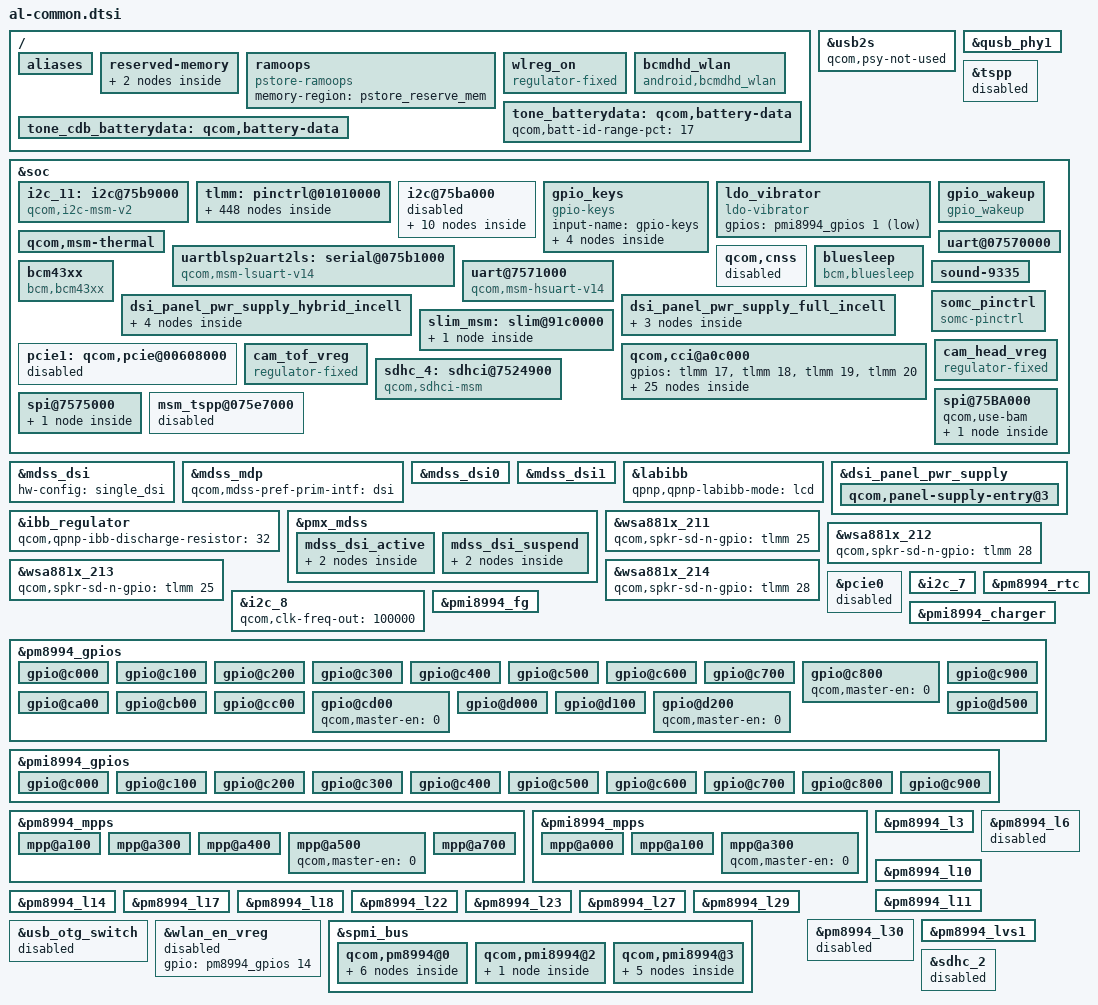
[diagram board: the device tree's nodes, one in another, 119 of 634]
/* 2017-11-15: File added by Sony Corporation */
/*
 * common dts for AL platforms
 *
 * Copyright 2017 Sony Corporation
 *
 * Original code is somc_tone-cdb-specific.dtsi and somc_tone-common.dtsi
 */
/* Copyright (c) 2012-2013, The Linux Foundation. All rights reserved.
 *
 * This program is free software; you can redistribute it and/or modify
 * it under the terms of the GNU General Public License version 2 and
 * only version 2 as published by the Free Software Foundation.
 *
 * This program is distributed in the hope that it will be useful,
 * but WITHOUT ANY WARRANTY; without even the implied warranty of
 * MERCHANTABILITY or FITNESS FOR A PARTICULAR PURPOSE.  See the
 * GNU General Public License for more details.
 */

#include "msm8996-mtp-for-somc.dtsi"
#include "msm8996-mdss-panels-for-somc.dtsi"

/ {
	aliases {
		uart2 = &blsp1_uart2;
		uart3 = &blsp1_uart3;
		i2c11 = &i2c_11;
		sdhc4 = &sdhc_4;
	};

	reserved-memory {
		debug_region: debug_region@83300000 {
			compatible = "removed-dma-pool", "qcom,debug_memory";
			no-map;
			reg = <0 0x83300000 0 0x100000>;
			label = "debug_mem";
		};

		pstore_reserve_mem: pstore_reserve_mem_region_region@83200000 {
			compatible = "removed-dma-pool";
			no-map;
			reg = <0 0x83200000 0 0x100000>;
		};
	};

	ramoops {
		compatible = "pstore-ramoops";
		memory-region = <&pstore_reserve_mem>;
	};
};

/* usb2s config */
&usb2s {
	status = "ok";
	qcom,psy-not-used;
};

&qusb_phy1 {
	/delete-property/ qcom,hold-reset;
};

&tspp {
	status = "disabled";
};



/* for bcmdhd */
/ {
	wlreg_on: wlreg_on {
		compatible = "regulator-fixed";
		regulator-name = "wlreg_on";
		gpio = <&tlmm 84 0>;
		regulator-min-microvolt = <1800000>;
		regulator-max-microvolt = <1800000>;
		startup-delay-us = <100>;
		enable-active-high;
	};
	bcmdhd_wlan: bcmdhd_wlan {
		compatible = "android,bcmdhd_wlan";
		gpios = <&tlmm 79 0x00>; /* WL_HOST_WAKE */
		wlreg_on-supply = <&wlreg_on>;
	};
};

&soc {
	/* I2C : BLSP11 */
	i2c_11: i2c@75b9000 { /* BLSP2 QUP4 */
		compatible = "qcom,i2c-msm-v2";
		#address-cells = <1>;
		#size-cells = <0>;
		reg-names = "qup_phys_addr";
		reg = <0x75b9000 0x1000>;
		interrupt-names = "qup_irq";
		interrupts = <0 105 0>;
		dmas = <&dma_blsp2 20 64 0x20000020 0x20>,
			<&dma_blsp2 21 32 0x20000020 0x20>;
		dma-names = "tx", "rx";
		qcom,master-id = <84>;
		qcom,clk-freq-out = <400000>;
		qcom,clk-freq-in  = <19200000>;
		clock-names = "iface_clk", "core_clk";
		clocks = <&clock_gcc clk_gcc_blsp2_ahb_clk>,
				<&clock_gcc clk_gcc_blsp2_qup5_i2c_apps_clk>;
		pinctrl-names = "i2c_active", "i2c_sleep";
		pinctrl-0 = <&i2c_11_active>;
		pinctrl-1 = <&i2c_11_sleep>;
	};

	tlmm: pinctrl@01010000 {
		i2c_11 {
			i2c_11_active: i2c_11_active {
				mux {
					pins = "gpio60", "gpio61";
					function = "blsp_i2c11";
				};

				config {
					pins = "gpio60", "gpio61";
					drive-strength = <4>;
					bias-disable;
				};
			};

			i2c_11_sleep: i2c_11_sleep {
				mux {
					pins = "gpio60", "gpio61";
					function = "blsp_i2c11";
				};

				config {
					pins = "gpio60", "gpio61";
					drive-strength = <4>;
					bias-pull-up;
				};
			};
		};
	};

	/* I2C : BLSP12 */
	i2c@75ba000 {
		pinctrl-0 = <&msm_gpio_87_act &msm_gpio_88_act>;
		pinctrl-1 = <&msm_gpio_87_sus &msm_gpio_88_sus>;
		status = "disabled";

		/delete-node/ synaptics@20;
		synaptics_clearpad@2c {
			compatible = "synaptics,clearpad";
			reg = <0x2c>;
			interrupt-parent = <&tlmm>;
			interrupts = <125 0x2>;
			synaptics,irq_gpio = <&tlmm 125 0x00>;
			post_probe_start = <0>;
			synaptics,firmware_name = "touch_module_id_0x%02x.img";
			flash_on_post_probe = <1>;
			flip_config = <0>;
			watchdog_enabled = <1>;
			watchdog_delay_ms = <3000>;
			charger_supported = <0>;
			pen_supported = <0>;
			glove_supported = <1>;
			cover_supported = <1>;
			touch_pressure_enabled = <1>;
			touch_size_enabled = <0>;
			touch_orientation_enabled = <0>;
			preset_x_max = <1079>;
			preset_y_max = <1919>;
			preset_n_fingers = <10>;
			wakeup_gesture_supported = <1>;
			wakeup_gesture_lpm_disabled = <1>;
			wakeup_gesture_timeout = <0>;
			wakeup_gesture_use_workaround_for_felica = <1>;
			chip_id = <0x38>;
			wakeup_gesture {
				double_tap {
					gesture_code = <0x0003>;
					event_00 {
						type = <2>; /* LOG */
						message = "=== DOUBLE TAP ===";
					};
					event_01 {
						type = <1>; /* KEY */
						code = <531>; /* TOUCHPAD_ON */
						down = <1>;
					};
					event_02 {
						type = <1>; /* KEY */
						code = <531>; /* TOUCHPAD_ON */
						down = <0>;
					};
					event_03 {
						type = <99>; /* END */
					};
				};
			};
			/* chip settings */
			clearpad_default {
				flash_default_timeout_ms = <20000>;
				calibrate_on_fwflash = <0>;
				calibration_supported = <0>;
				hwreset_delay_for_powerup_ms = <60>;
				interrupt_default_wait_ms = <1000>;
			};
			S3330 {
				flash_default_timeout_ms = <20000>;
				calibrate_on_fwflash = <0>;
				calibration_supported = <0>;
				hwreset_delay_for_powerup_ms = <60>;
				interrupt_default_wait_ms = <1000>;
			};
			S332U {
				flash_default_timeout_ms = <20000>;
				calibration_supported = <1>;
				hwreset_delay_for_powerup_ms = <60>;
				interrupt_default_wait_ms = <1000>;
				calibrate_on_fwflash = <0>;
			};
		};
	};

	gpio_keys {
		compatible = "gpio-keys";
		input-name = "gpio-keys";

		vol_dn {
			label = "volume_down";
			gpios = <&pm8994_gpios 2 0x1>;
			linux,input-type = <1>;
			linux,code = <114>;
			/delete-property/ gpio-key,wakeup;
			debounce-interval = <15>;
		};

		vol_up {
			label = "volume_up";
			gpios = <&pm8994_gpios 3 0x1>;
			linux,input-type = <1>;
			linux,code = <115>;
			/delete-property/ gpio-key,wakeup;
			debounce-interval = <15>;
		};

		cam_snapshot {
			label = "cam_snapshot";
			gpios = <&pm8994_gpios 4 0x1>;
			linux,input-type = <1>;
			linux,code = <0x2fe>;
			gpio-key,wakeup;
			debounce-interval = <15>;
		};

		cam_focus {
			label = "cam_focus";
			gpios = <&pm8994_gpios 5 0x1>;
			linux,input-type = <1>;
			linux,code = <0x210>;
			gpio-key,wakeup;
			debounce-interval = <15>;
		};
	};

	ldo_vibrator {
		compatible = "ldo-vibrator";
		gpios = <&pmi8994_gpios 1 1>;
	};

	gpio_wakeup {
		compatible = "gpio_wakeup";
		irq_gpio_num = <4>;
		irq_gpios = <9 77 117 125>;
	};

	qcom,msm-thermal {
		qcom,limit-temp = <85>;
		qcom,core-limit-temp = <95>;
        };

	/* UART: BLSP9 */
	uartblsp2uart2ls: serial@075b1000 {
		compatible = "qcom,msm-lsuart-v14";
		reg = <0x75b1000 0x1000>;
		interrupts = <0 115 0>;
		clocks = <&clock_gcc clk_gcc_blsp2_uart3_apps_clk>,
			 <&clock_gcc clk_gcc_blsp2_ahb_clk>;
		clock-names = "core_clk", "iface_clk";
		status = "ok";
		pinctrl-names = "default";
		pinctrl-0 = <&msm_gpio_49 &msm_gpio_50>;
	};

        /* UART: BLSP2 */
	uart@07570000 {
		reg = <0x07570000 0x1000>,
		      <0x7544000 0x2b000>;
		interrupt-map = <0 &intc 0 0 108 0
		                1 &intc 0 0 238 0
		                2 &tlmm 42 0>;
		/delete-property/ qcom,inject-rx-on-wakeup;
		/delete-property/ qcom,rx-char-to-inject;
		qcom,bam-tx-ep-pipe-index = <2>;
		qcom,bam-rx-ep-pipe-index = <3>;
		pinctrl-names = "default", "sleep", "on";
		pinctrl-0 = <&msm_gpio_41_suspend &msm_gpio_42_suspend &msm_gpio_43_suspend &msm_gpio_44_suspend>;
		pinctrl-1 = <&msm_gpio_41_suspend &msm_gpio_42_suspend &msm_gpio_43_suspend &msm_gpio_44_suspend>;
		pinctrl-2 = <&msm_gpio_41_active &msm_gpio_42_active &msm_gpio_43_active &msm_gpio_44_active>;
		status = "okay";
	};

	qcom,cnss {
		status = "disable";
	};

	uart@7571000 {
		compatible = "qcom,msm-hsuart-v14";
		reg = <0x7571000 0x1000>,
		    <0x7544000 0x2b000>;
		interrupt-parent = <&blsp1_uart3>;
		interrupt-map = <0 &intc 0 0 109 0
		                1 &intc 0 0 238 0
		                2 &tlmm 46 0>;
		/delete-property/ qcom,inject-rx-on-wakeup;
		/delete-property/ qcom,rx-char-to-inject;
		pinctrl-names = "default", "sleep", "on";
		pinctrl-0 = <&msm_gpio_45_suspend &msm_gpio_46_suspend &msm_gpio_47_suspend &msm_gpio_48_suspend>;
		pinctrl-1 = <&msm_gpio_45_suspend &msm_gpio_46_suspend &msm_gpio_47_suspend &msm_gpio_48_suspend>;
		pinctrl-2 = <&msm_gpio_45_active &msm_gpio_46_active &msm_gpio_47_active &msm_gpio_48_active>;
		status = "okay";
	};

	bluesleep {
		compatible = "bcm,bluesleep";
		bt_host_wake = <&tlmm 82 0x00>; /* BT_HOST_WAKE */
		bt_ext_wake = <&tlmm 81 0x00>; /* BT_DEV_WAKE */
		interrupt-parent = <&tlmm>;
		interrupts = <82 0>;
		interrupt-names = "host_wake";
		pinctrl-names = "wake_irq_active", "wake_irq_suspend";
		pinctrl-0 = <&msm_gpio_82_active &msm_gpio_81>;
		pinctrl-1 = <&msm_gpio_82_suspend &msm_gpio_81>;
	};

	bcm43xx {
		compatible = "bcm,bcm43xx";
		bcm,reg-on-gpio = <&tlmm 83 0x00>; /* BT_REG_ON */
		pinctrl-names = "default", "sleep";
		pinctrl-0 = <&msm_gpio_83>;
		pinctrl-1 = <&msm_gpio_83>;
	};

	dsi_panel_pwr_supply_hybrid_incell: dsi_panel_pwr_supply_hybrid_incell {
		#address-cells = <1>;
		#size-cells = <0>;

		qcom,panel-supply-entry@0 {
			reg = <0>;
			qcom,supply-name = "vddio";
			qcom,supply-min-voltage = <1800000>;
			qcom,supply-max-voltage = <1800000>;
			qcom,supply-enable-load = <62000>;
			qcom,supply-disable-load = <80>;
		};

		qcom,panel-supply-entry@1 {
			reg = <1>;
			qcom,supply-name = "lab";
			qcom,supply-min-voltage = <4600000>;
			qcom,supply-max-voltage = <6000000>;
			qcom,supply-enable-load = <100000>;
			qcom,supply-disable-load = <100>;
		};

		qcom,panel-supply-entry@2 {
			reg = <2>;
			qcom,supply-name = "ibb";
			qcom,supply-min-voltage = <4600000>;
			qcom,supply-max-voltage = <6000000>;
			qcom,supply-enable-load = <100000>;
			qcom,supply-disable-load = <100>;
		};

		qcom,panel-supply-entry@3 {
			reg = <2>;
			qcom,supply-name = "touch-avdd";
			qcom,supply-min-voltage = <2800000>;
			qcom,supply-max-voltage = <3200000>;
			qcom,supply-enable-load = <100000>;
			qcom,supply-disable-load = <100>;
		};
	};

	dsi_panel_pwr_supply_full_incell: dsi_panel_pwr_supply_full_incell {
		#address-cells = <1>;
		#size-cells = <0>;

		qcom,panel-supply-entry@0 {
			reg = <0>;
			qcom,supply-name = "vddio";
			qcom,supply-min-voltage = <1800000>;
			qcom,supply-max-voltage = <1800000>;
			qcom,supply-enable-load = <62000>;
			qcom,supply-disable-load = <80>;
		};

		qcom,panel-supply-entry@1 {
			reg = <1>;
			qcom,supply-name = "lab";
			qcom,supply-min-voltage = <4600000>;
			qcom,supply-max-voltage = <6000000>;
			qcom,supply-enable-load = <100000>;
			qcom,supply-disable-load = <100>;
		};

		qcom,panel-supply-entry@2 {
			reg = <2>;
			qcom,supply-name = "ibb";
			qcom,supply-min-voltage = <4600000>;
			qcom,supply-max-voltage = <6000000>;
			qcom,supply-enable-load = <100000>;
			qcom,supply-disable-load = <100>;
		};

		/delete-node/ qcom,panel-supply-entry@3;
	};

	pcie1: qcom,pcie@00608000 {
		status = "disabled";
	};

	sound-9335 {
		qcom,msm-mbhc-hphl-swh = <1>;
		/delete-property/ qcom,hph-en1-gpio;
		/delete-property/ qcom,hph-en0-gpio;
		/delete-property/ qcom,us-euro-gpios;
		qcom,ear-en-gpios = <&pm8994_gpios 13 0>;
		qcom,audio-routing =
			"AIF4 VI", "MCLK",
			"RX_BIAS", "MCLK",
			"LDO_H", "MCLK",
			"AMIC1", "MIC BIAS1",
			"MIC BIAS1", "Handset Mic",
			"AMIC2", "MIC BIAS2",
			"MIC BIAS2", "Headset Mic",
			"AMIC3", "MIC BIAS3",
			"MIC BIAS3", "ANCRight Headset Mic",
			"AMIC4", "MIC BIAS4",
			"MIC BIAS4", "ANCLeft Headset Mic",
			"LDO_H", "AHC VSNS",
			"DMIC0", "MIC BIAS1",
			"MIC BIAS1", "Digital Mic0",
			"DMIC3", "MIC BIAS4",
			"MIC BIAS4", "Digital Mic3",
			"SpkrLeft IN", "SPK1 OUT";
	};

	slim_msm: slim@91c0000 {
		tasha_codec {
			qcom,cdc-micbias1-mv = <2000>;
			qcom,cdc-micbias2-mv = <2000>;
			qcom,cdc-micbias3-mv = <2000>;
			qcom,cdc-micbias4-mv = <2000>;
			qcom,cdc-dmic-sample-rate = <2400000>;
		};
	};

	somc_pinctrl: somc_pinctrl {
		compatible = "somc-pinctrl";
		pinctrl-names = "platform_common_default",
				"product_common_default",
				"variant_default";
		pinctrl-0 = <&msm_gpio_4
				&msm_gpio_5 &msm_gpio_6 &msm_gpio_7 &msm_gpio_8 &msm_gpio_9
				&msm_gpio_10 &msm_gpio_11 &msm_gpio_12 &msm_gpio_13
				&msm_gpio_14 &msm_gpio_15 &msm_gpio_16 &msm_gpio_17
				&msm_gpio_18 &msm_gpio_19 &msm_gpio_20 &msm_gpio_21
				&msm_gpio_22 &msm_gpio_23 &msm_gpio_24 &msm_gpio_25
				&msm_gpio_26 &msm_gpio_27 &msm_gpio_28 &msm_gpio_29
				&msm_gpio_30 &msm_gpio_31 &msm_gpio_32 &msm_gpio_33
				&msm_gpio_34 &msm_gpio_35 &msm_gpio_38 &msm_gpio_39 &msm_gpio_40
				&msm_gpio_41_suspend &msm_gpio_42_suspend &msm_gpio_43_suspend &msm_gpio_44_suspend
				&msm_gpio_45_suspend &msm_gpio_46_suspend &msm_gpio_47_suspend &msm_gpio_48_suspend
				&msm_gpio_49 &msm_gpio_50 &msm_gpio_51 &msm_gpio_52
				&msm_gpio_55 &msm_gpio_56 &msm_gpio_57 &msm_gpio_58
				&msm_gpio_59 &msm_gpio_60 &msm_gpio_61 &msm_gpio_62
				&msm_gpio_63 &msm_gpio_69 &msm_gpio_73 &msm_gpio_74
				&msm_gpio_75 &msm_gpio_76 &msm_gpio_77 &msm_gpio_78
				&msm_gpio_79 &msm_gpio_80 &msm_gpio_81 &msm_gpio_82_suspend &msm_gpio_83
				&msm_gpio_84 &msm_gpio_89 &msm_gpio_90
				&msm_gpio_108 &msm_gpio_112 &msm_gpio_116
				&msm_gpio_118 &msm_gpio_119
				&msm_gpio_121 &msm_gpio_122 &msm_gpio_123 &msm_gpio_124
				&msm_gpio_125 &msm_gpio_126 &msm_gpio_127 &msm_gpio_128
				&msm_gpio_130 &msm_gpio_131
				&msm_gpio_132 &msm_gpio_138 &msm_gpio_141 &msm_gpio_142 &msm_gpio_143>;

		/* If product common default setting is needed,
		   fill pinctrl-1 value in <product>_common.dtsi */
		pinctrl-1 = <&msm_gpio_105 &msm_gpio_110 &msm_gpio_111>;

		/* If variant specific default setting is needed,
		   fill pinctrl-2 value in <variant>.dtsi */
		pinctrl-2 = <>;

		/* If variant specific default setting is needed,
		   fill pinctrl-3 value in <variant>.dtsi */
		pinctrl-3 = <>;
	};

	qcom,cci@a0c000 {
		gpios = <&tlmm 17 0>,
			<&tlmm 18 0>,
			<&tlmm 19 0>,
			<&tlmm 20 0>;

		qcom,i2c_fast_mode {
			qcom,hw-thigh = <43>;
			qcom,hw-tlow = <64>;
			qcom,hw-tsu-sto = <41>;
			qcom,hw-tsu-sta = <41>;
			qcom,hw-thd-dat = <25>;
			qcom,hw-thd-sta = <35>;
			qcom,hw-tbuf = <64>;
			qcom,hw-scl-stretch-en = <0>;
			qcom,hw-trdhld = <6>;
			qcom,hw-tsp = <3>;
			qcom,cci-clk-src = <37500000>;
			status = "ok";
		};

		qcom,i2c_fast_plus_mode {
			qcom,hw-thigh = <16>;
			qcom,hw-tlow = <22>;
			qcom,hw-tsu-sto = <17>;
			qcom,hw-tsu-sta = <18>;
			qcom,hw-thd-dat = <16>;
			qcom,hw-thd-sta = <15>;
			qcom,hw-tbuf = <19>;
			qcom,hw-scl-stretch-en = <1>;
			qcom,hw-trdhld = <3>;
			qcom,hw-tsp = <3>;
			qcom,cci-clk-src = <37500000>;
			status = "ok";
		};

		qcom,camera@0 {
			cell-index = <0>;
			compatible = "qcom,sony_camera_0";
			reg = <0x0>;
			status = "ok";
			qcom,slave-id = <0x20 0x0 0x0000>;
			qcom,csiphy-sd-index = <0>;
			qcom,csid-sd-index = <0>;
			qcom,mount-angle = <0>;
			qcom,sensor-name = "sony_camera_0";
			cam_vdig-supply = <&pm8994_l3>;
			cam_vana-supply = <&pm8994_l17>;
			cam_vio-supply = <&pm8994_lvs1>;
			qcom,cam-vreg-name = "cam_vdig", "cam_vana", "cam_vio";
			qcom,cam-vreg-type = <0 0 1 0>;
			qcom,cam-vreg-min-voltage = <1000000 2700000 0>;
			qcom,cam-vreg-max-voltage = <1000000 2700000 0>;
			qcom,cam-vreg-op-mode = <105000 85600 0>;
			qcom,gpio-no-mux = <0>;
			pinctrl-names = "cam_default", "cam_suspend";
			pinctrl-0 = <&cam_sensor_mclk0_active &cam_sensor_rear_active>;
			pinctrl-1 = <&cam_sensor_mclk0_suspend &cam_sensor_rear_suspend>;
			gpios = <&tlmm 13 0>, <&tlmm 30 0>;
			qcom,gpio-reset = <1>;
			qcom,gpio-req-tbl-num = <0 1>;
			qcom,gpio-req-tbl-flags = <1 0>;
			qcom,gpio-req-tbl-label = "CAMIF_MCLK0", "CAM_RESET0";
			qcom,csi-lane-assign = <0x4320>;
			qcom,csi-lane-mask = <0x1F>;
			qcom,sensor-position = <0>;
			qcom,sensor-mode = <1>;
			qcom,cci-master = <0>;
			clocks = <&clock_mmss clk_mclk0_clk_src>, <&clock_mmss clk_camss_mclk0_clk>;
			clock-names = "cam_src_clk", "cam_clk";
			sony,i2c_addr = <0x20>;
			sony,eeprom_addr = <0xA8>;
			sony,eeprom_type = <3>;
			sony,eeprom_max_len = <2048>;
			sony,gpio_af = <0>;
			sony,subdev_code = <0x3007>;
			sony_camera_module_0: sony,camera_modules {
			};
		};

		qcom,camera@1 {
			cell-index = <1>;
			compatible = "qcom,sony_camera_1";
			reg = <0x1>;
			status = "ok";
			qcom,slave-id = <0x20 0x0000 0x0000>;
			qcom,csiphy-sd-index = <1>;
			qcom,csid-sd-index = <1>;
			qcom,mount-angle = <0>;
			qcom,sensor-name = "sony_camera_1";
			cam_vdig-supply = <&cam_head_vreg>;
			cam_vana-supply = <&cam_head_vreg>;
			cam_vio-supply = <&pm8994_lvs1>;
			qcom,cam-vreg-name = "cam_vdig", "cam_vio";
			qcom,cam-vreg-type = <0 1>;
			qcom,cam-vreg-min-voltage = <0 0>;
			qcom,cam-vreg-max-voltage = <0 0>;
			qcom,cam-vreg-op-mode = <0 0>;
			qcom,gpio-no-mux = <0>;
			pinctrl-names = "cam_default", "cam_suspend";
			pinctrl-0 = <&cam_sensor_mclk1_active &cam_sensor_front_active>;
			pinctrl-1 = <&cam_sensor_mclk1_suspend &cam_sensor_front_suspend>;
			gpios = <&tlmm 14 0>, <&tlmm 23 0>;
			qcom,gpio-reset = <1>;
			qcom,gpio-req-tbl-num = <0 1>;
			qcom,gpio-req-tbl-flags = <1 0>;
			qcom,gpio-req-tbl-label = "CAMIF_MCLK1", "CAM_RESET1";
			qcom,csi-lane-assign = <0x4320>;
			qcom,csi-lane-mask = <0x1F>;
			qcom,sensor-position = <1>;
			qcom,sensor-mode = <1>;
			qcom,cci-master = <1>;
			clocks = <&clock_mmss clk_mclk1_clk_src>, <&clock_mmss clk_camss_mclk1_clk>;
			clock-names = "cam_src_clk", "cam_clk";
			sony,i2c_addr = <0x20>;
			sony,eeprom_addr = <0xA8>;
			sony,eeprom_type = <3>;
			sony,eeprom_max_len = <2048>;
			sony,gpio_af = <0>;
			sony,subdev_code = <0x3007>;
			sony_camera_module_1: sony,camera_modules {
			};
		};

		qcom,camera@2 {
			cell-index = <2>;
			compatible = "qcom,sony_camera_2";
			reg = <0x2>;
			status = "ok";
			qcom,slave-id = <0x20 0x0000 0x0000>;
			qcom,csiphy-sd-index = <2>;
			qcom,csid-sd-index = <2>;
			qcom,mount-angle = <0>;
			qcom,sensor-name = "sony_camera_2";
			cam_vdig-supply = <&pm8994_l27>;
			cam_vana-supply = <&cam_tof_vreg>; /* TOF_PWR_EN */
			cam_vio-supply = <&pm8994_lvs1>;
			qcom,cam-vreg-name = "cam_vdig", "cam_vana", "cam_vio";
			qcom,cam-vreg-type = <0 0 1>;
			qcom,cam-vreg-min-voltage = <1200000 0 0>;
			qcom,cam-vreg-max-voltage = <1200000 0 0>;
			qcom,cam-vreg-op-mode = <80000 0 0>;
			qcom,gpio-no-mux = <0>;
			pinctrl-names = "cam_default", "cam_suspend";
			pinctrl-0 = <&cam_sensor_mclk2_active &cam_sensor_front2_active>;
			pinctrl-1 = <&cam_sensor_mclk2_suspend &cam_sensor_front2_suspend>;
			gpios = <&tlmm 15 0>, <&tlmm 26 0>, <&tlmm 8 0>, <&tlmm 69 0>;
			qcom,gpio-reset = <1>;
			qcom,gpio-req-tbl-num = <0 1 2 3>;
			qcom,gpio-req-tbl-flags = <1 0 0 0>;
			qcom,gpio-req-tbl-label = "CAMIF_MCLK2", "CAM_RESET2", "CAM_HV_EN", "CAM_LD_EN";
			qcom,csi-lane-assign = <0x4320>;
			qcom,csi-lane-mask = <0x1F>;
			qcom,sensor-position = <2>;
			qcom,sensor-mode = <1>;
			qcom,cci-master = <1>;
			clocks = <&clock_mmss clk_mclk2_clk_src>, <&clock_mmss clk_camss_mclk2_clk>;
			clock-names = "cam_src_clk", "cam_clk";
			sony,i2c_addr = <0x20>;
			sony,eeprom_addr = <0xA0>;
			sony,eeprom_type = <255>;
			sony,eeprom_max_len = <2048>;
			sony,gpio_af = <0>;
			sony,subdev_code = <0x3007>;
			sony_camera_module_2: sony,camera_modules {
			};
		};
	};

	cam_head_vreg: cam_head_vreg {
		compatible = "regulator-fixed";
		regulator-name = "cam_head_vreg";
		startup-delay-up = <0>;
		enable-active-high;
		gpio = <&tlmm 22 0>;
	};

	cam_tof_vreg: cam_tof_vreg {
		compatible = "regulator-fixed";
		regulator-name = "cam_tof_vreg";
		startup-delay-up = <0>;
		enable-active-high;
		gpio = <&tlmm 24 0>;
	};

	/* sdc4 */
	sdhc_4: sdhci@7524900 {
		compatible = "qcom,sdhci-msm";
		reg = <0x7524900 0x314>, <0x7524000 0x800>;
		reg-names = "hc_mem", "core_mem";

		interrupts = <0 129 0>, <0 227 0>, <0 228 0>;
		interrupt-names = "hc_irq", "pwr_irq", "sdiowakeup_irq";

		clock-names = "iface_clk", "core_clk";
		clocks = <&clock_gcc clk_gcc_sdcc4_ahb_clk>,
		<&clock_gcc clk_gcc_sdcc4_apps_clk>;

		qcom,large-address-bus;
		qcom,bus-width = <4>;

		qcom,msm-bus,name = "sdhc4";
		qcom,msm-bus,num-cases = <9>;
		qcom,msm-bus,num-paths = <1>;
		qcom,msm-bus,vectors-KBps = <80 512 0 0>, /* No vote */
			<80 512 1600 3200>, /* 400 KB/s*/
			<80 512 80000 160000>, /* 20 MB/s */
			<80 512 100000 200000>, /* 25 MB/s */
			<80 512 200000 400000>, /* 50 MB/s */
			<80 512 400000 800000>, /* 100 MB/s */
			<80 512 400000 800000>, /* 200 MB/s */
			<80 512 400000 800000>, /* 400 MB/s */
			<80 512 2048000 4096000>; /* Max. bandwidth */
		qcom,bus-bw-vectors-bps = <0 400000 20000000 25000000 50000000
			100000000 200000000 400000000 4294967295>;

		qcom,pm-qos-cpu-groups = <0x03 0x0c>;
		qcom,pm-qos-cmdq-latency-us = <70 70>, <70 70>;
		qcom,pm-qos-legacy-latency-us = <70 70>, <70 70>;
		qcom,pm-qos-irq-type = "affine_cores";
		qcom,pm-qos-irq-cpu = <0>;
		qcom,pm-qos-irq-latency = <70 70>;
		status = "ok";
		vdd-io-supply = <&pm8994_s4>;
		qcom,vdd-io-voltage-level = <1800000 1800000>;
		qcom,vdd-io-current-level = <200 15000>;
		qcom,vdd-io-always-on;
		pinctrl-names = "active", "sleep";
		pinctrl-0 = <&sdc4_clk_on &sdc4_cmd_on &sdc4_data0_on &sdc4_data1_on
			&sdc4_data2_on &sdc4_data3_on>;
		pinctrl-1 = <&sdc4_clk_off &sdc4_cmd_off &sdc4_data0_off &sdc4_data1_off
			&sdc4_data2_off &sdc4_data3_off>;
		qcom,clk-rates = <400000 20000000 25000000 50000000 100000000>;
		qcom,bus-speed-mode = "SDR12", "SDR25", "SDR50", "DDR50";
		qcom,nonremovable;
		qcom,core_3_0v_support;
		cd-post;
		wifi-host;
	};

	/* SPI : BLSP12 */
	spi@75BA000{
		status = "okay";
		qcom,use-bam;
		eye0@0 {
			compatible="spidev";
			reg = <0>;
			spi-max-frequency =<38400000>;
		};
	};
	/* SPI : BLSP1 */
	spi@7575000 {
		status = "okay";
		qcom,use-bam;
		pinctrl-0 = <&spi_0_active>;
		pinctrl-1 = <&spi_0_sleep>;
		eye0@0 {
			compatible="spidev";
			reg = <0>;
			spi-max-frequency =<38400000>;
		};
	};

	/* disable tspp */
	msm_tspp@075e7000 {
		status = "disable";
	};
};

&sony_camera_module_0 {
	module_names = "LGI20BS0", "SUN20BS0";
	default_module_name = "LGI20BS0";

	LGI20BS0 {
		mount_angle = <90>;
		sensor_rotation = <0>;
		sensor_facing = <0>;
		total_pixel_number_w = <5264>;
		total_pixel_number_h = <3992>;
		active_pixel_number_x = <656>;
		active_pixel_number_y = <0>;
		active_pixel_number_w = <3936>;
		active_pixel_number_h = <3936>;
		min_focus_distance = <0>;
		hyper_focal_distance = <3679>;
		diagonal_len = "7.87";
		unit_cell_size_w = "1.20";
		unit_cell_size_h = "1.20";
		min_f_number = "2.80";
		max_f_number = "2.80";
		has_3a = <0>;
		has_focus_actuator = <0>;
		need_standby_af = <0>;
		i2c_freq_mode = <1>;
		has_pdaf = <0>;
		has_rs = <1>;
		pdaf_free_area_num = <0>;
		pdaf_fixed_area_size_w = <0>;
		pdaf_fixed_area_size_h = <0>;
		pll_num = <26>;
		pll = <1134 1134 1134 1134 1134 1134 1134 1134 1134 1134 1134 1134 1134 1134 1134 1134 1134 1134 1134 1134 1134 1134 1134 1134 1134 1134>;
		power_off {
			commands =
				"I2C_WRITE",
				"GPIO_RESET",
				"CAM_CLK",
				"CAM_VDIG",
				"CAM_VIO",
				"CAM_VANA",
				"EXIT";
			CAM_VDIG = <0 0xFFFFFFFF 0 1>;
			CAM_VIO = <1 0xFFFFFFFF 0 1>;
			CAM_VANA = <2 0xFFFFFFFF 0 99>;
			GPIO_RESET = <5 0x0 0 1>;
			CAM_CLK = <6 0xFFFFFFFF 0 1>;
			I2C_WRITE = <7 0x0100 0 100>;
			EXIT = <8 0x0 0 0>;
		};
		power_on {
			commands =
				"CAM_VDIG",
				"CAM_VIO",
				"CAM_VANA",
				"CAM_CLK",
				"GPIO_RESET",
				"EXIT";
			CAM_VDIG = <0 1000 76700 1>;
			CAM_VIO = <1 0 0 1>;
			CAM_VANA = <2 2700 39200 1>;
			GPIO_RESET = <5 1 0 1>;
			CAM_CLK = <6 0 0 10>;
			EXIT = <8 0x0 0 0>;
		};
	};

	SUN20BS0 {
		mount_angle = <90>;
		sensor_rotation = <0>;
		sensor_facing = <0>;
		total_pixel_number_w = <5264>;
		total_pixel_number_h = <3992>;
		active_pixel_number_x = <656>;
		active_pixel_number_y = <0>;
		active_pixel_number_w = <3936>;
		active_pixel_number_h = <3936>;
		min_focus_distance = <0>;
		hyper_focal_distance = <3679>;
		diagonal_len = "7.87";
		unit_cell_size_w = "1.20";
		unit_cell_size_h = "1.20";
		min_f_number = "2.80";
		max_f_number = "2.80";
		has_3a = <0>;
		has_focus_actuator = <0>;
		need_standby_af = <0>;
		i2c_freq_mode = <1>;
		has_pdaf = <0>;
		has_rs = <1>;
		pdaf_free_area_num = <0>;
		pdaf_fixed_area_size_w = <0>;
		pdaf_fixed_area_size_h = <0>;
		pll_num = <26>;
		pll = <1134 1134 1134 1134 1134 1134 1134 1134 1134 1134 1134 1134 1134 1134 1134 1134 1134 1134 1134 1134 1134 1134 1134 1134 1134 1134>;
		power_off {
			commands =
				"I2C_WRITE",
				"GPIO_RESET",
				"CAM_CLK",
				"CAM_VDIG",
				"CAM_VIO",
				"CAM_VANA",
				"EXIT";
			CAM_VDIG = <0 0xFFFFFFFF 0 1>;
			CAM_VIO = <1 0xFFFFFFFF 0 1>;
			CAM_VANA = <2 0xFFFFFFFF 0 99>;
			GPIO_RESET = <5 0x0 0 1>;
			CAM_CLK = <6 0xFFFFFFFF 0 1>;
			I2C_WRITE = <7 0x0100 0 100>;
			EXIT = <8 0x0 0 0>;
		};
		power_on {
			commands =
				"CAM_VDIG",
				"CAM_VIO",
				"CAM_VANA",
				"CAM_CLK",
				"GPIO_RESET",
				"EXIT";
			CAM_VDIG = <0 1000 76700 1>;
			CAM_VIO = <1 0 0 1>;
			CAM_VANA = <2 2700 39200 1>;
			GPIO_RESET = <5 1 0 1>;
			CAM_CLK = <6 0 0 10>;
			EXIT = <8 0x0 0 0>;
		};
	};

	qcom,msm-imem@66bf000 {
		#address-cells = <1>;
		#size-cells = <0>;
		debug_base@18 {
			compatible = "qcom,msm-imem-debug_base";
			reg = <0x44 4>;
		};
	};
};

&sony_camera_module_1 {
	module_names = "LGI20BS0", "SUN20BS0";
	default_module_name = "LGI20BS0";

	LGI20BS0 {
		mount_angle = <90>;
		sensor_rotation = <0>;
		sensor_facing = <1>;
		total_pixel_number_w = <5264>;
		total_pixel_number_h = <3992>;
		active_pixel_number_x = <656>;
		active_pixel_number_y = <0>;
		active_pixel_number_w = <3936>;
		active_pixel_number_h = <3936>;
		min_focus_distance = <0>;
		hyper_focal_distance = <3679>;
		diagonal_len = "7.87";
		unit_cell_size_w = "1.20";
		unit_cell_size_h = "1.20";
		min_f_number = "2.80";
		max_f_number = "2.80";
		has_3a = <0>;
		has_focus_actuator = <0>;
		need_standby_af = <0>;
		i2c_freq_mode = <1>;
		has_pdaf = <0>;
		has_rs = <1>;
		pdaf_free_area_num = <0>;
		pdaf_fixed_area_size_w = <0>;
		pdaf_fixed_area_size_h = <0>;
		pll_num = <26>;
		pll = <1134 1134 1134 1134 1134 1134 1134 1134 1134 1134 1134 1134 1134 1134 1134 1134 1134 1134 1134 1134 1134 1134 1134 1134 1134 1134>;
		power_off {
			commands =
				"I2C_WRITE",
				"GPIO_RESET",
				"CAM_CLK",
				"CAM_VDIG",
				"CAM_VIO",
				"CAM_VANA",
				"EXIT";
			CAM_VIO = <1 0xFFFFFFFF 0 1>;
			CAM_VDIG = <0 0xFFFFFFFF 0 99>;
			CAM_VANA = <2 0xFFFFFFFF 0 99>;
			GPIO_RESET = <5 0x0 0 1>;
			CAM_CLK = <6 0xFFFFFFFF 0 1>;
			I2C_WRITE = <7 0x0100 0 100>;
			EXIT = <8 0x0 0 0>;
		};
		power_on {
			commands =
				"CAM_VIO",
				"CAM_VANA",
				"CAM_VDIG",
				"CAM_CLK",
				"GPIO_RESET",
				"EXIT";
			CAM_VIO = <1 0 0 1>;
			CAM_VANA = <2 0 0 1>;
			CAM_VDIG = <0 0 0 1>;
			GPIO_RESET = <5 1 0 1>;
			CAM_CLK = <6 0 0 1>;
			EXIT = <8 0x0 0 0>;
		};
	};

	SUN20BS0 {
		mount_angle = <90>;
		sensor_rotation = <0>;
		sensor_facing = <1>;
		total_pixel_number_w = <5264>;
		total_pixel_number_h = <3992>;
		active_pixel_number_x = <656>;
		active_pixel_number_y = <0>;
		active_pixel_number_w = <3936>;
		active_pixel_number_h = <3936>;
		min_focus_distance = <0>;
		hyper_focal_distance = <3679>;
		diagonal_len = "7.87";
		unit_cell_size_w = "1.20";
		unit_cell_size_h = "1.20";
		min_f_number = "2.80";
		max_f_number = "2.80";
		has_3a = <0>;
		has_focus_actuator = <0>;
		need_standby_af = <0>;
		i2c_freq_mode = <1>;
		has_pdaf = <0>;
		has_rs = <1>;
		pdaf_free_area_num = <0>;
		pdaf_fixed_area_size_w = <0>;
		pdaf_fixed_area_size_h = <0>;
		pll_num = <26>;
		pll = <1134 1134 1134 1134 1134 1134 1134 1134 1134 1134 1134 1134 1134 1134 1134 1134 1134 1134 1134 1134 1134 1134 1134 1134 1134 1134>;
		power_off {
			commands =
				"I2C_WRITE",
				"GPIO_RESET",
				"CAM_CLK",
				"CAM_VDIG",
				"CAM_VIO",
				"CAM_VANA",
				"EXIT";
			CAM_VIO = <1 0xFFFFFFFF 0 1>;
			CAM_VDIG = <0 0xFFFFFFFF 0 99>;
			CAM_VANA = <2 0xFFFFFFFF 0 99>;
			GPIO_RESET = <5 0x0 0 1>;
			CAM_CLK = <6 0xFFFFFFFF 0 1>;
			I2C_WRITE = <7 0x0100 0 100>;
			EXIT = <8 0x0 0 0>;
		};
		power_on {
			commands =
				"CAM_VIO",
				"CAM_VANA",
				"CAM_VDIG",
				"CAM_CLK",
				"GPIO_RESET",
				"EXIT";
			CAM_VIO = <1 0 0 1>;
			CAM_VANA = <2 0 0 1>;
			CAM_VDIG = <0 0 0 1>;
			GPIO_RESET = <5 1 0 1>;
			CAM_CLK = <6 0 0 1>;
			EXIT = <8 0x0 0 0>;
		};
	};
};

&sony_camera_module_2 {
	module_names = "SKTOF000";
	default_module_name = "SKTOF000";

	SKTOF000 {
		mount_angle = <0>;
		sensor_rotation = <0>;
		sensor_facing = <2>;
		total_pixel_number_w = <5264>;
		total_pixel_number_h = <3992>;
		active_pixel_number_x = <8>;
		active_pixel_number_y = <48>;
		active_pixel_number_w = <5248>;
		active_pixel_number_h = <3936>;
		min_focus_distance = <0>;
		hyper_focal_distance = <3679>;
		diagonal_len = "7.87";
		unit_cell_size_w = "1.20";
		unit_cell_size_h = "1.20";
		min_f_number = "2.00";
		max_f_number = "2.00";
		has_3a = <0>;
		has_focus_actuator = <0>;
		need_standby_af = <0>;
		i2c_freq_mode = <1>;
		has_pdaf = <0>;
		has_rs = <1>;
		pdaf_free_area_num = <0>;
		pdaf_fixed_area_size_w = <0>;
		pdaf_fixed_area_size_h = <0>;
		pll_num = <0>;
		pll = <0>;
		power_off {
			commands =
				"GPIO_RESET",
				"CAM_CLK",
				"GPIO_LD",
				"GPIO_HV",
				"CAM_VIO",
				"CAM_VDIG",
				"CAM_VANA",
				"EXIT";
			GPIO_RESET = <5 0x0 0 10>;
			CAM_CLK = <6 0xFFFFFFFF 0 10>;
			GPIO_LD = <10 0 0 1>;
			GPIO_HV = <9 0 0 2>;
			CAM_VIO = <1 0xFFFFFFFF 0 0>;
			CAM_VDIG = <0 0xFFFFFFFF 0 0>;
			CAM_VANA = <2 0xFFFFFFFF 0 100>;
			EXIT = <8 0x0 0 0>;
		};
		power_on {
			commands =
				"CAM_VANA",
				"CAM_VDIG",
				"CAM_VIO",
				"GPIO_HV",
				"GPIO_LD",
				"CAM_CLK",
				"GPIO_RESET",
				"EXIT";
			CAM_VANA = <2 0 0 0>; /* TOF_PWR_EN */
			CAM_VDIG = <0 1200 80000 0>;
			CAM_VIO = <1 0 0 2>;
			GPIO_HV = <9 1 0 1>; /* TOF_HV_PWR_EN */
			GPIO_LD = <10 1 0 100>; /* TOF_LD_EN */
			CAM_CLK = <6 24000000 0 1>;
			GPIO_RESET = <5 1 0 10>;
			EXIT = <8 0x0 0 0>;
		};
	};
};

&mdss_dsi {
	hw-config = "single_dsi";
};

/* Graphics */
&mdss_mdp {
	qcom,mdss-pref-prim-intf = "dsi";
};

&mdss_dsi0 {
	vddio-supply = <&pm8994_s4>;
	touch-avdd-supply = <&pm8994_l22>;
	pinctrl-names = "mdss_default", "mdss_sleep", "mdss_touch_active", "mdss_touch_suspend";
	pinctrl-0 = <&mdss_dsi_active &mdss_te_active>;
	pinctrl-1 = <&mdss_dsi_suspend &mdss_te_suspend>;
	pinctrl-2 = <&mdss_touch_active>;
	pinctrl-3 = <&mdss_touch_suspend>;
	qcom,platform-te-gpio = <&tlmm 10 0>;
	qcom,platform-reset-gpio = <&tlmm 8 0>;
	qcom,platform-vddio-gpio = <&tlmm 51 0>;
	qcom,platform-touch-vddio-gpio = <&tlmm 50 0>;
	qcom,platform-touch-reset-gpio = <&tlmm 89 0>;
	qcom,platform-touch-int-gpio = <&tlmm 125 0>;
};

&mdss_dsi1 {
	vddio-supply = <&pm8994_s4>;
	touch-avdd-supply = <&pm8994_l22>;
	pinctrl-names = "mdss_default", "mdss_sleep";
	pinctrl-0 = <&mdss_dsi_active &mdss_te_active>;
	pinctrl-1 = <&mdss_dsi_suspend &mdss_te_suspend>;
	qcom,platform-te-gpio = <&tlmm 10 0>;
	qcom,platform-reset-gpio = <&tlmm 8 0>;
};

&labibb {
	status = "ok";
	qpnp,qpnp-labibb-mode = "lcd";
};

&ibb_regulator {
	qcom,qpnp-ibb-discharge-resistor = <32>;
};

&dsi_panel_pwr_supply {
		qcom,panel-supply-entry@3 {
			reg = <2>;
			qcom,supply-name = "touch_vdd";
			qcom,supply-min-voltage = <2800000>;
			qcom,supply-max-voltage = <3200000>;
			qcom,supply-enable-load = <100000>;
			qcom,supply-disable-load = <100>;
		};
};

&pmx_mdss {
	mdss_dsi_active: mdss_dsi_active {
		mux {
			pins = "gpio8";
			function = "gpio";
		};

		config {
			pins = "gpio8";
			drive-strength = <2>; /* 2 mA */
			bias-disable = <0>; /* no pull */
			output-high;
		};
	};
	mdss_dsi_suspend: mdss_dsi_suspend {
		mux {
			pins = "gpio8";
			function = "gpio";
		};

		config {
			pins = "gpio8";
			drive-strength = <2>; /* 2 mA */
			/delete-property/ bias-pull-down;
			bias-disable = <0>; /* no pull */
			output-low;
		};
	};
};

/* Audio */
&wsa881x_211 {
	qcom,spkr-sd-n-gpio = <&tlmm 25 0>;
};

&wsa881x_212 {
	qcom,spkr-sd-n-gpio = <&tlmm 28 0>;
};

&wsa881x_213 {
	qcom,spkr-sd-n-gpio = <&tlmm 25 0>;
};

&wsa881x_214 {
	qcom,spkr-sd-n-gpio = <&tlmm 28 0>;
};

/* Wlan */
&pcie0 {
	status = "disabled";
};

/* For Charger */
&i2c_7 {
	/delete-node/ silabs4705@11;
	/delete-node/ smb1351-charger@1d;
};

/* Charger */
/{
	tone_batterydata: qcom,battery-data {
		qcom,batt-id-range-pct = <17>;
		/delete-node/ qcom,itech-3000mah;
	};

	tone_cdb_batterydata: qcom,battery-data {
		#include "batterydata-tone-dora-send.dtsi"
	};
};

/* For Battery IC */
&i2c_8 {
	qcom,clk-freq-out = <100000>;
};

&pm8994_rtc {
	qcom,qpnp-rtc-write = <1>;
	qcom,qpnp-rtc-alarm-pwrup = <1>;
};

&pmi8994_fg {
	qcom,battery-data = <&tone_batterydata>;
	qcom,battery-data = <&tone_cdb_batterydata>;
	qcom,hot-bat-decidegc = <550>;
	qcom,warm-bat-decidegc = <450>;
	qcom,cool-bat-decidegc = <100>;
	qcom,cold-bat-decidegc = <50>;
	qcom,cl-max-increment-deciperc = <0>;
	qcom,cl-max-decrement-deciperc = <20>;
	qcom,cl-max-start-capacity = <40>;
	qcom,hold-soc-while-full;
	qcom,resume-soc-raw = <0xF3>;
};

&pmi8994_charger {
	/delete-property/ qcom,parallel-usb-min-current-ma;
	/delete-property/ qcom,parallel-9v-usb-min-current-ma;
	qcom,charge-unknown-battery;
	qcom,usb_dp-vadc = <&pmi8994_vadc>;
	qcom,usb_dm-vadc = <&pmi8994_vadc>;
	qcom,charging-disabled;
};

&pm8994_gpios {
	/* GPIO_1: (P_SENSE_CNTL) */
	gpio@c000 {
		qcom,master-en = <1>;		/* Enable */
		qcom,src-sel = <0>;			/* GPIO */
		qcom,mode = <1>;			/* Out */
		qcom,output-type = <1>;		/* NMOS */
		qcom,vin-sel = <0>;			/* VPH */
		qcom,out-strength = <1>;	/* Low */
		qcom,invert = <1>;			/* High */
		status = "ok";
	};

	/* GPIO_2: VOL_DOWN_N */
	gpio@c100 {
		qcom,src-sel = <0>;		/* GPIO */
		qcom,mode = <0>;		/* In */
		qcom,vin-sel = <2>;		/* S4 */
		qcom,pull = <0>;		/* PU */
		qcom,master-en = <1>;		/* Enable */
		status = "ok";
	};

	/* GPIO_3: VOL_UP_N */
	gpio@c200 {
		qcom,src-sel = <0>;		/* GPIO */
		qcom,mode = <0>;		/* In */
		qcom,vin-sel = <2>;		/* S4 */
		qcom,pull = <0>;		/* PU */
		qcom,master-en = <1>;		/* Enable */
		status = "ok";
	};

	/* GPIO_4: SNAPSHOT_N */
	gpio@c300 {
		qcom,src-sel = <0>;		/* GPIO */
		qcom,mode = <0>;		/* In */
		qcom,vin-sel = <2>;		/* S4 */
		qcom,pull = <0>;		/* PU */
		qcom,master-en = <1>;		/* Enable */
		status = "ok";
	};

	/* GPIO_5: FOCUS_N */
	gpio@c400 {
		qcom,src-sel = <0>;		/* GPIO */
		qcom,mode = <0>;		/* In */
		qcom,vin-sel = <2>;		/* S4 */
		qcom,pull = <0>;		/* PU */
		qcom,master-en = <1>;		/* Enable */
		status = "ok";
	};

	/* GPIO_6: PGOOD_SMB1351 */
	gpio@c500 {
		qcom,src-sel = <0>;		/* GPIO */
		qcom,mode = <0>;		/* In */
		qcom,vin-sel = <2>;		/* S4 */
		qcom,pull = <0>;		/* PU */
		qcom,master-en = <1>;		/* Enable */
		status = "ok";
	};

	/* GPIO_7: PSD XSHUT FR */
	gpio@c600 {
		qcom,src-sel = <0>;		/* GPIO */
		qcom,mode = <1>;		/* Out */
		qcom,output-type = <0x0>;
		qcom,invert = <0>;		/* Low */
		qcom,pull = <0x5>;
		qcom,vin-sel = <2>;		/* S4 */
		qcom,out-strength = <1>;	/* Low */
		qcom,src-sel = <0x0>;
		qcom,master-en = <1>;		/* Enable */
		status = "ok";
	};

	/* GPIO_8: PSD XSHUT FL */
	gpio@c700 {
		qcom,src-sel = <0>;		/* GPIO */
		qcom,mode = <1>;		/* Out */
		qcom,output-type = <0x0>;
		qcom,invert = <0>;		/* Low */
		qcom,pull = <0x5>;
		qcom,vin-sel = <2>;		/* S4 */
		qcom,out-strength = <1>;	/* Low */
		qcom,src-sel = <0x0>;
		qcom,master-en = <1>;		/* Enable */
		status = "ok";
	};

	/* GPIO_9: NC */
	gpio@c800 {
		qcom,master-en = <0>;		/* Disable */
		status = "okay";
	};

	/* GPIO_10: NFC_CLK_REQ */
	gpio@c900 {
		qcom,src-sel = <0>;		/* GPIO */
		qcom,mode = <0>;		/* In */
		qcom,vin-sel = <2>;		/* S4 */
		qcom,pull = <4>;		/* PD */
		qcom,master-en = <1>;		/* Enable */
		status = "ok";
	};

	/* GPIO_11: WPC_EN_B */
	gpio@ca00 {
                qcom,src-sel = <0>;             /* GPIO */
                qcom,mode = <1>;                /* Out */
                qcom,vin-sel = <2>;             /* S4 */
                qcom,out-strength = <1>;        /* Low */
                qcom,invert = <0>;              /* Low */
                qcom,master-en = <1>;           /* Enable */
                status = "ok";
		qcom,output-type = <0>;		/* CMOS */
	};

	/* GPIO_12: WPC_CHG_END */
	gpio@cb00 {
		qcom,src-sel = <0>;             /* GPIO */
                qcom,mode = <1>;                /* Out */
                qcom,vin-sel = <2>;             /* S4 */
                qcom,out-strength = <1>;        /* Low */
                qcom,invert = <0>;              /* Low */
                qcom,master-en = <1>;           /* Enable */
                status = "ok";
		qcom,output-type = <0>;		/* CMOS */
	};

	/* GPIO_13: EAR_EN */
	gpio@cc00 {
		qcom,src-sel = <0>;		/* GPIO */
		qcom,mode = <1>;		/* Out */
		qcom,output-type = <0>;		/* CMOS */
		qcom,vin-sel = <2>;		/* S4 */
		qcom,out-strength = <1>;	/* Low */
		qcom,invert = <0>;		/* Low */
		qcom,master-en = <1>;		/* Enable */
		status = "ok";
	};

	/* GPIO_14: EAR_EN */
	gpio@cd00 {
		qcom,master-en = <0>;		/* Disable */
		status = "okay";
	};

	/* GPIO_15: PM_DIVCLK1 */
	/* Follow QTI */

	/* GPIO_16: PMI_CLK */
	/* Follow QTI */

	/* GPIO_17: DIVCLK3 */
	gpio@d000 {
		qcom,master-en = <1>;		/* Enable */
		qcom,src-sel = <2>;		/* SPECIAL_FUNCTION1 */
		qcom,mode = <1>;		/* Out */
		qcom,output-type = <0>;		/* CMOS */
		qcom,vin-sel = <2>;		/* S4 */
		qcom,out-strength = <1>;	/* Low */
		qcom,pull = <5>;		/* NP */
		qcom,invert = <0>;		/* Low */
		status = "ok";
	};


	/* GPIO_18: WL_SLEEP_CLK */
	gpio@d100 {
		qcom,src-sel = <3>;		/* SPECIAL_FUNCTION2 */
		qcom,mode = <1>;		/* Out */
		qcom,output-type = <0>;		/* CMOS */
		qcom,vin-sel = <2>;		/* S4 */
		qcom,out-strength = <1>;	/* Low */
		qcom,pull = <5>;		/* NP */
		qcom,master-en = <1>;		/* Enable */
		status = "ok";
	};

	/* GPIO_19: NC */
	gpio@d200 {
		qcom,master-en = <0>;		/* Disable */
		status = "okay";
	};

	/* GPIO_20: PMIC_SPON */
	/* Follow QTI */

	/* GPIO_21: UIM_BATT_ALARM */
	/* Follow QTI */

	/* GPIO_22: PMK_SLEEP_CLK */
	gpio@d500 {
		qcom,master-en = <1>;		/* Enable */
		qcom,src-sel = <0>;		/* GPIO */
		qcom,mode = <0>;		/* In */
		qcom,vin-sel = <2>;		/* S4 */
		qcom,pull = <4>;		/* PD */
		status = "ok";
	};

	/* VCTRL: SSC_PWR_EN */
	/* Follow QTI */
};
&pmi8994_gpios {

	/* GPIO_1: VIB_LDO_EN */
	gpio@c000 {
		qcom,src-sel = <0>;		/* GPIO */
		qcom,mode = <1>;		/* Out */
		qcom,output-type = <0>;		/* CMOS */
		qcom,vin-sel = <2>;		/* S4 */
		qcom,out-strength = <1>;	/* Low */
		qcom,invert = <0>;		/* Low */
		qcom,master-en = <1>;		/* Enable */
		status = "okay";
	};

	/* GPIO_2: PS_DCDC_EN */
	gpio@c100 {
		qcom,src-sel = <0>;		/* GPIO */
		qcom,mode = <1>;		/* Out */
		qcom,output-type = <0>;		/* CMOS */
		qcom,vin-sel = <2>;		/* S4 */
		qcom,out-strength = <1>;	/* Low */
		qcom,invert = <0>;		/* Low */
		qcom,master-en = <1>;		/* Enable */
		status = "okay";
	};

	/* GPIO_3: LOW_TEMP_IND */
	gpio@c200 {
		qcom,src-sel = <0>;		/* GPIO */
		qcom,mode = <1>;		/* Out */
		qcom,output-type = <0>;		/* CMOS */
		qcom,vin-sel = <2>;		/* S4 */
		qcom,out-strength = <1>;	/* Low */
		qcom,invert = <0>;		/* Low */
		qcom,master-en = <1>;		/* Enable */
		status = "okay";
	};

	/* GPIO_4: CHG_STAT1 */
	gpio@c300 {
		qcom,src-sel = <0>;		/* GPIO */
		qcom,mode = <0>;		/* In */
		qcom,vin-sel = <2>;		/* S4 */
		qcom,pull = <0>;		/* PU */
		qcom,master-en = <1>;		/* Enable */
		status = "okay";
	};

	/* GPIO_5: CHG_STAT2 */
	gpio@c400 {
		qcom,src-sel = <0>;		/* GPIO */
		qcom,mode = <0>;		/* In */
		qcom,vin-sel = <2>;		/* S4 */
		qcom,pull = <0>;		/* PU */
		qcom,master-en = <1>;		/* Enable */
		status = "okay";
	};

	/* GPIO_6: NC */
	gpio@c500 {
		qcom,src-sel = <0>;		/* GPIO */
		qcom,mode = <1>;		/* Out */
		qcom,output-type = <0>;		/* CMOS */
		qcom,vin-sel = <2>;		/* S4 */
		qcom,out-strength = <1>;	/* Low */
		qcom,invert = <0>;		/* Low */
		qcom,master-en = <1>;		/* Enable */
		status = "okay";
	};

	/* GPIO_7: NC */
	gpio@c600 {
		qcom,src-sel = <0>;		/* GPIO */
		qcom,mode = <1>;		/* Out */
		qcom,output-type = <0>;		/* CMOS */
		qcom,vin-sel = <0>;		/* VPH */
		qcom,out-strength = <1>;	/* Low */
		qcom,invert = <0>;		/* Low */
		qcom,master-en = <1>;		/* Enable */
		status = "okay";
	};

	/* GPIO_8: NC */
	gpio@c700 {
		qcom,src-sel = <0>;		/* GPIO */
		qcom,mode = <1>;		/* Out */
		qcom,output-type = <0>;		/* CMOS */
		qcom,vin-sel = <2>;		/* S4 */
		qcom,out-strength = <1>;	/* Low */
		qcom,invert = <0>;		/* Low */
		qcom,master-en = <1>;		/* Enable */
		status = "okay";
	};

	/* GPIO_9: CHG_EN_N */
	gpio@c800 {
		qcom,src-sel = <0>;		/* GPIO */
		qcom,mode = <1>;		/* Out */
		qcom,output-type = <0>;		/* CMOS */
		qcom,vin-sel = <0>;		/* VPH */
		qcom,out-strength = <1>;	/* Low */
		qcom,invert = <0>;		/* Low */
		qcom,master-en = <1>;		/* Enable */
		status = "okay";
	};

	/* GPIO_10: LTE_VUSB_IN */
	gpio@c900 {
		qcom,src-sel = <0>;		/* GPIO */
		qcom,mode = <1>;		/* Out */
		qcom,output-type = <0>;		/* CMOS */
		qcom,vin-sel = <0>;		/* VPH_PWR */
		qcom,out-strength = <1>;	/* Low */
		qcom,invert = <0>;		/* Low */
		qcom,master-en = <1>;		/* Enable */
		status = "okay";
	};
};

&pm8994_mpps {
	/* MPP_1: SDC_UIM_VBIAS */
	/* Follow QTI */

	/* MPP_2: LCD_ID_ADC */
	mpp@a100 {
		qcom,mode = <4>;		/* AIN */
		qcom,ain-route = <1>;		/* AMUX 6(Ch #17)*/
		qcom,master-en = <1>;		/* Enable */
		status = "okay";
	};

	/* MPP_3: VREF_DACX */
	/* Follow QTI */

	/* Follow QTI */
	/* MPP_4: HDMI_EN */
	mpp@a300 { /* MPP 4 */
		/* HDMI_5v_vreg regulator enable */
		qcom,mode = <1>;		/* Digital output */
		qcom,output-type = <0>;		/* CMOS logic */
		qcom,vin-sel = <2>;		/* S4 1.8V */
		qcom,src-sel = <0>;		/* Constant */
		qcom,master-en = <1>;		/* Enable GPIO */
		qcom,invert = <0>;
		status = "okay";
	};

	/* MPP_5: ALS_OUT_ANA */
	mpp@a400 {
		qcom,mode = <4>;		/* AIN */
		qcom,src-sel = <0>;		/* MPP Constant */
		qcom,ain-route = <0>;		/* AMUX 5 */
		qcom,master-en = <1>;		/* Enable */
		status = "okay";
	};

	/* MPP_6: NC(STAT_SMB1351) */
	mpp@a500 {
		qcom,master-en = <0>;		/* Disable */
		status = "okay";
	};

	/* MPP_7: NC */
	/* Follow QTI */

	/* MPP_8: RF_ID */
	mpp@a700 {
		qcom,mode = <4>;		/* AIN */
		qcom,ain-route = <3>;		/* AMUX 8(Ch #39)*/
		qcom,master-en = <1>;		/* Enable */
		status = "okay";
	};
};

&pmi8994_mpps {
	/* MPP_1: USB_ID_DISCHG */
	mpp@a000 {
		qcom,mode = <0>;		/* DIN */
		qcom,vin-sel = <0>;		/* VPH */
		qcom,master-en = <1>;		/* Enable */
		status = "okay";
	};

	/* MPP_2: FLASH_LED_NOW */
	mpp@a100 {
		qcom,mode = <0>;		/* DIN */
		qcom,master-en = <1>;	/* Enable */
		qcom,vin-sel = <2>;		/* 1.8v */
		status = "okay";
	};

	/* MPP_3: PMI_SPON */
	/* Follow QTI */

	/* MPP_4: NC (Reserved for EXT_FET_WLED_PWR_EN) */
	mpp@a300 {
		qcom,master-en = <0>;		/* Disable */
		status = "okay";
	};
};

/* Regulator config */
/* pm8994_s1 */
/* Follow QTI */

/* pm8994_s2 */
/* Follow QTI */

/* pm8994_s3 */
/* Follow QTI */

/* pm8994_s4 */
/* Follow QTI */

/* pm8994_s5 */
/* Follow QTI */

/* pm8994_s6 */
/* Follow QTI */

/* pm8994_s7 */
/* Follow QTI */

/* pm8994_s8 */
/* Follow QTI */

/* pm8994_s9 */
/* Follow QTI */

/* pm8994_s10 */
/* Follow QTI */

/* pm8994_s11 */
/* Follow QTI */

/* pm8994_s12 */
/* Follow QTI */

/* pm8994_l1 */
/* Follow QTI */

/* pm8994_l2 */
/* Follow QTI */

&pm8994_l3 {
	qcom,regulator-type = <0>;	/* LDO */
	qcom,init-enable = <0>;
	qcom,init-ldo-mode = <1>;
	qcom,init-pin-ctrl-enable = <0>;
	qcom,init-pin-ctrl-mode = <0>;
	regulator-min-microvolt = <1000000>;
	regulator-max-microvolt = <1100000>;
	qcom,init-voltage = <1000000>;
	status = "okay";
};

/* pm8994_l4 */
/* Follow QTI */

/* pm8994_l5 */
/* Follow QTI */

&pm8994_l6 {
	status = "disabled";
};

/* pm8994_l7 */
/* Follow QTI */

/* pm8994_l8 */
/* Follow QTI */

/* pm8994_l9 */
/* Follow QTI */

/* pm8994_l10 */
&pm8994_l10 {
	qcom,regulator-type = <0>;	/* LDO */
	qcom,init-enable = <0>;
	qcom,init-ldo-mode = <1>;
	qcom,init-pin-ctrl-enable = <0>;
	qcom,init-pin-ctrl-mode = <0>;
	regulator-min-microvolt = <3000000>;
	regulator-max-microvolt = <3000000>;
	qcom,init-voltage = <3000000>;
	status = "okay";
};

&pm8994_l11 {
	qcom,regulator-type = <0>;	/* LDO */
	qcom,init-enable = <0>;
	qcom,init-ldo-mode = <1>;
	qcom,init-pin-ctrl-enable = <0>;
	qcom,init-pin-ctrl-mode = <0>;
	regulator-min-microvolt = <1000000>;
	regulator-max-microvolt = <1200000>;
	qcom,init-voltage = <1100000>;
	status = "okay";
};

/* pm8994_l12 */
/* Follow QTI */

/* pm8994_l13 */
/* Follow QTI */

&pm8994_l14 {
	qcom,regulator-type = <0>;	/* LDO */
	qcom,init-enable = <0>;
	qcom,init-ldo-mode = <1>;
	qcom,init-pin-ctrl-enable = <0>;
	qcom,init-pin-ctrl-mode = <0>;
	regulator-min-microvolt = <1700000>;
	regulator-max-microvolt = <1900000>;
	qcom,init-voltage = <1800000>;
	status = "okay";
};

/* pm8994_l15 */
/* Follow QTI */

/* pm8994_l16 */
/* Follow QTI */

&pm8994_l17 {
	qcom,regulator-type = <0>;	/* LDO */
	qcom,init-enable = <0>;
	qcom,init-ldo-mode = <1>;
	qcom,init-pin-ctrl-enable = <0>;
	qcom,init-pin-ctrl-mode = <0>;
	regulator-min-microvolt = <2200000>;
	regulator-max-microvolt = <2900000>;
	qcom,init-voltage = <2800000>;
	status = "okay";
};

&pm8994_l18 {
	qcom,regulator-type = <0>;	/* LDO */
	qcom,init-enable = <0>;
	qcom,init-ldo-mode = <1>;
	qcom,init-pin-ctrl-enable = <0>;
	qcom,init-pin-ctrl-mode = <0>;
	regulator-min-microvolt = <3075000>;
	regulator-max-microvolt = <3075000>;
	qcom,init-voltage = <3075000>;
	status = "okay";
};

/* pm8994_l19 */
/* Follow QTI */

/* pm8994_l20 */
/* Follow QTI */

/* pm8994_l21 */
/* Follow QTI */

&pm8994_l22 {
	qcom,regulator-type = <0>;	/* LDO */
	qcom,init-enable = <0>;
	qcom,init-ldo-mode = <1>;
	qcom,init-pin-ctrl-enable = <0>;
	qcom,init-pin-ctrl-mode = <0>;
	regulator-min-microvolt = <3000000>;
	regulator-max-microvolt = <3000000>;
	qcom,init-voltage = <3000000>;
	status = "okay";
};

&pm8994_l23 {
	qcom,regulator-type = <0>;	/* LDO */
	qcom,init-enable = <0>;
	qcom,init-ldo-mode = <1>;
	qcom,init-pin-ctrl-enable = <0>;
	qcom,init-pin-ctrl-mode = <0>;
	regulator-min-microvolt = <3000000>;
	regulator-max-microvolt = <3000000>;
	qcom,init-voltage = <3000000>;
	status = "okay";
};

/* pm8994_l24 */
/* Follow QTI */

/* pm8994_l25 */
/* Follow QTI */

/* pm8994_l26 */
/* Follow QTI */

&pm8994_l27 {
	qcom,regulator-type = <0>;	/* LDO */
	qcom,init-enable = <0>;
	qcom,init-ldo-mode = <1>;
	qcom,init-pin-ctrl-enable = <0>;
	qcom,init-pin-ctrl-mode = <0>;
	regulator-min-microvolt = <1200000>;
	regulator-max-microvolt = <1200000>;
	qcom,init-voltage = <1200000>;
	status = "okay";
};

/* pm8994_l28 */
/* Follow QTI */

&pm8994_l29 {
	qcom,regulator-type = <0>;	/* LDO */
	qcom,init-enable = <0>;
	qcom,init-ldo-mode = <1>;
	qcom,init-pin-ctrl-enable = <0>;
	qcom,init-pin-ctrl-mode = <0>;
	regulator-min-microvolt = <3075000>;
	regulator-max-microvolt = <3075000>;
	qcom,init-voltage = <3075000>;
	status = "okay";
};

&pm8994_l30 {
	status = "disabled";
};

/* pm8994_l31 */
/* Follow QTI */

/* pm8994_l32 */
/* Follow QTI */

&pm8994_lvs1 {
	qcom,regulator-type = <2>;	/* VS */
	qcom,init-enable = <0>;
	qcom,init-pin-ctrl-enable = <0>;
	qcom,init-pin-ctrl-mode = <0>;
	status = "okay";
};

/* pm8994_lvs2 */
/* Follow QTI */

/* pmi8994_s1 */
/* Follow QTI */

/* pmi8994_s2 */
/* Follow QTI */

/* pmi8994_s3 */
/* Follow QTI */

/* pmi8994_boostbypass */
/* Follow QTI */

/* pmi8994_boost_5v */
/* Follow QTI */

&usb_otg_switch {
        status = "disabled";
};

&wlan_en_vreg {
        gpio = <&pm8994_gpios 14 0>;
        status = "disabled";
};

&tlmm {
	/* GPIO_0 : FP_SPI_MOSI */
	msm_gpio_0: msm_gpio_0 {
		mux {
			pins = "gpio0";
			function = "gpio";
		};

		config {
			pins = "gpio0";
			drive-strength = <2>;
			bias-disable;
			output-low;
		};
	};

	/* GPIO_1 : FP_SPI_MISO */
	msm_gpio_1: msm_gpio_1 {
		mux {
			pins = "gpio1";
			function = "gpio";
		};

		config {
			pins = "gpio1";
			drive-strength = <2>;
			bias-pull-down;
		};
	};

	/* GPIO_2 : FP_SPI_CS_N */
	msm_gpio_2: msm_gpio_2 {
		mux {
			pins = "gpio2";
			function = "gpio";
		};

		config {
			pins = "gpio2";
			drive-strength = <2>;
			bias-disable;
			output-low;
		};
	};

	/* GPIO_3 : FP_SPI_CLK */
	msm_gpio_3: msm_gpio_3 {
		mux {
			pins = "gpio3";
			function = "gpio";
		};

		config {
			pins = "gpio3";
			drive-strength = <2>;
			bias-disable;
			output-low;
		};
	};

	/* GPIO_4 : DEBUG_UART_TX */
	msm_gpio_4: msm_gpio_4 {
		mux {
			pins = "gpio4";
			function = "blsp_uart8";
		};

		config {
			pins = "gpio4";
			drive-strength = <4>;
			bias-disable;
		};
	};

	/* GPIO_5 : DEBUG_UART_RX */
	msm_gpio_5: msm_gpio_5 {
		mux {
			pins = "gpio5";
			function = "blsp_uart8";
		};

		config {
			pins = "gpio5";
			drive-strength = <2>;
			bias-pull-up;
		};
	};

	/* GPIO_6 : NFC_I2C_SDA */
	msm_gpio_6: msm_gpio_6 {
		mux {
			pins = "gpio6";
			function = "blsp_i2c8";
		};

		config {
			pins = "gpio6";
			drive-strength = <2>;
			bias-disable;
		};
	};

	/* GPIO_7 : NFC_I2C_SCL */
	msm_gpio_7: msm_gpio_7 {
		mux {
			pins = "gpio7";
			function = "blsp_i2c8";
		};

		config {
			pins = "gpio7";
			drive-strength = <2>;
			bias-disable;
		};
	};

	/* GPIO_8 : TOF_HV_PWR_EN */
	msm_gpio_8: msm_gpio_8 {
		mux {
			pins = "gpio8";
			function = "gpio";
		};

		config {
			pins = "gpio8";
			drive-strength = <2>;
			bias-disable;
			output-low;
		};
	};

	/* GPIO_9 : FRONT_IR_SENSE_INT */
	msm_gpio_9: msm_gpio_9 {
		mux {
			pins = "gpio9";
			function = "gpio";
		};

		config {
			pins = "gpio9";
			drive-strength = <2>;
			bias-pull-down;
			input-enable;
		};
	};

	/* GPIO_10 : SPI GPIO */
	msm_gpio_10: msm_gpio_10 {
		mux {
			pins = "gpio10";
			function = "gpio";
		};

		config {
			pins = "gpio10";
			drive-strength = <4>;
			bias-disable;
			output-low;
		};
	};

	/* GPIO_11 : MHL_INT */
	msm_gpio_11: msm_gpio_11 {
		mux {
			pins = "gpio11";
			function = "gpio";
		};

		config {
			pins = "gpio11";
			drive-strength = <2>;
			/delete-property/ bias-disable;
			/delete-property/ output-low;
			bias-pull-up;
		};
	};

	/* GPIO_12 : CM_PWR_EN */
	msm_gpio_12: msm_gpio_12 {
		mux {
			pins = "gpio12";
			function = "gpio";
		};

		config {
			pins = "gpio12";
			drive-strength = <2>;
			bias-disable;
			output-low;
		};
	};

	/* GPIO_13 : CAM0_MCLK */
	msm_gpio_13: msm_gpio_13 {
		mux {
			pins = "gpio13";
			function = "cam_mclk";
		};

		config {
			pins = "gpio13";
			drive-strength = <6>;
			bias-disable;
		};
	};

	/* GPIO_14 : CAM1_MCLK */
	msm_gpio_14: msm_gpio_14 {
		mux {
			pins = "gpio14";
			function = "cam_mclk";
		};

		config {
			pins = "gpio14";
			drive-strength = <6>;
			bias-disable;
			/delete-property/ output-low;
		};
	};

	/* GPIO_15 : CAM2_MCLK */
	msm_gpio_15: msm_gpio_15 {
		mux {
			pins = "gpio15";
			function = "cam_mclk";
		};

		config {
			pins = "gpio15";
			drive-strength = <6>;
			bias-disable;
		};
	};

	/* GPIO_16 : SW_SERVICE */
	msm_gpio_16: msm_gpio_16 {
		mux {
			pins = "gpio16";
			function = "gpio";
		};

		config {
			pins = "gpio16";
			drive-strength = <2>;
			bias-pull-up;
		};
	};

	/* GPIO_17 : CCI_I2C_SDA0 */
	msm_gpio_17: msm_gpio_17 {
		mux {
			pins = "gpio17";
			function = "cci_i2c";
		};

		config {
			pins = "gpio17";
			drive-strength = <2>;
			bias-disable;
		};
	};

	/* GPIO_18 : CCI_I2C_SCL0 */
	msm_gpio_18: msm_gpio_18 {
		mux {
			pins = "gpio18";
			function = "cci_i2c";
		};

		config {
			pins = "gpio18";
			drive-strength = <2>;
			bias-disable;
		};
	};

	/* GPIO_19 : CCI_I2C_SDA1 */
	msm_gpio_19: msm_gpio_19 {
		mux {
			pins = "gpio19";
			function = "cci_i2c";
		};

		config {
			pins = "gpio19";
			drive-strength = <2>;
			bias-disable;
		};
	};

	/* GPIO_20 : CCI_I2C_SCL1 */
	msm_gpio_20: msm_gpio_20 {
		mux {
			pins = "gpio20";
			function = "cci_i2c";
		};

		config {
			pins = "gpio20";
			drive-strength = <2>;
			bias-disable;
		};
	};

	/* GPIO_21 : FP_RESET_N */
	msm_gpio_21: msm_gpio_21 {
		mux {
			pins = "gpio21";
			function = "gpio";
		};

		config {
			pins = "gpio21";
			drive-strength = <2>;
			bias-disable;
			output-low;
		};
	};

	/* GPIO_21 : FP_RESET_N, state device active*/
	msm_gpio_21_output_high: msm_gpio_21_output_high {
		mux {
			pins = "gpio21";
			function = "gpio";
		};

		config {
			pins = "gpio21";
			drive-strength = <2>;
			bias-disable;
			output-high;
		};
	};

	/* GPIO_22 : CAM_PWR_EN */
	msm_gpio_22: msm_gpio_22 {
		mux {
			pins = "gpio22";
			function = "gpio";
		};

		config {
			pins = "gpio22";
			drive-strength = <2>;
			bias-disable;
			output-low;
		};
	};

	/* GPIO_23 : CAM_HEAD_RESET_N */
	msm_gpio_23: msm_gpio_23 {
		mux {
			pins = "gpio23";
			function = "gpio";
		};

		config {
			pins = "gpio23";
			drive-strength = <2>;
			bias-disable;
			output-low;
		};
	};

	/* GPIO_24 : TOF_PWR_EN */
	msm_gpio_24: msm_gpio_24 {
		mux {
			pins = "gpio24";
			function = "gpio";
		};

		config {
			pins = "gpio24";
			drive-strength = <2>;
			bias-disable;
			output-low;
		};
	};

	/* GPIO_25 : USB_CABLE_SENSE_EN */
	msm_gpio_25: msm_gpio_25 {
		mux {
			pins = "gpio25";
			function = "gpio";
		};

		config {
			pins = "gpio25";
			drive-strength = <2>;
			bias-disable;
			output-low;
		};
	};

	/* GPIO_26 : CAM2_STANDBY */
	msm_gpio_26: msm_gpio_26 {
		mux {
			pins = "gpio26";
			function = "gpio";
		};

		config {
			pins = "gpio26";
			drive-strength = <2>;
			bias-disable;
			output-low;
		};
	};

	/* GPIO_27 : SPKR_AMP_EN1 */
	msm_gpio_27: msm_gpio_27 {
		mux {
			pins = "gpio27";
			function = "gpio";
		};

		config {
			pins = "gpio27";
			drive-strength = <2>;
			bias-disable;
			output-low;
		};
	};

	/* GPIO_28 : SPKR_AMP_EN2 */
	msm_gpio_28: msm_gpio_28 {
		mux {
			pins = "gpio28";
			function = "gpio";
		};

		config {
			pins = "gpio28";
			drive-strength = <2>;
			bias-disable;
			output-low;
		};
	};

	/* GPIO_29 : UIM2_DETECT_EN */
	msm_gpio_29: msm_gpio_29 {
		mux {
			pins = "gpio29";
			function = "gpio";
		};

		config {
			pins = "gpio29";
			drive-strength = <2>;
			bias-disable;
			output-low;
		};
	};

	/* GPIO_30 : CAM_BODY_RESET_N */
	msm_gpio_30: msm_gpio_30 {
		mux {
			pins = "gpio30";
			function = "gpio";
		};

		config {
			pins = "gpio30";
			drive-strength = <2>;
			bias-disable;
			output-low;
		};
	};

	/* GPIO_31 : HDMI_CEC */
	msm_gpio_31: msm_gpio_31 {
		mux {
			pins = "gpio31";
			function = "hdmi_cec";
		};

		config {
			pins = "gpio31";
			drive-strength = <2>;
			/delete-property/ bias-disable;
			/delete-property/ output-low;
			bias-pull-up;
		};
	};

	/* GPIO_32 : HDMI_DDC_CLK */
	msm_gpio_32: msm_gpio_32 {
		mux {
			pins = "gpio32";
			function = "hdmi_ddc";
		};

		config {
			pins = "gpio32";
			drive-strength = <2>;
			/delete-property/ bias-disable;
			/delete-property/ output-low;
			bias-pull-up;
		};
	};

	/* GPIO_33 : HDMI_DDC_DATA */
	msm_gpio_33: msm_gpio_33 {
		mux {
			pins = "gpio33";
			function = "hdmi_ddc";
		};

		config {
			pins = "gpio33";
			drive-strength = <2>;
			/delete-property/ bias-disable;
			/delete-property/ output-low;
			bias-pull-up;
		};
	};

	/* GPIO_34 : HDMI_HOT_PLUG_DET */
	msm_gpio_34: msm_gpio_34 {
		mux {
			pins = "gpio34";
			function = "hdmi_hot";
		};

		config {
			pins = "gpio34";
			drive-strength = <2>;
			/delete-property/ bias-disable;
			/delete-property/ output-low;
			bias-pull-down;
		};
	};

	/* GPIO_35 : MP_XRST */
	msm_gpio_35: msm_gpio_35 {
		mux {
			pins = "gpio35";
			function = "gpio";
		};

		config {
			pins = "gpio35";
			drive-strength = <2>;
			bias-disable;
			output-low;
		};
	};

	/* GPIO_36 : MPWD_DETECTION */
        msm_gpio_36: msm_gpio_36 {
	        mux {
			pins = "gpio36";
			function = "gpio";
		};

		config {
			pins = "gpio36";
			drive-strength = <2>;
			bias-pull-up;
			input-enable;
		};
	};

	/* GPIO_37 : PCIE_WL_WAKE_N */
	/* Follow QTI */

	/* GPIO_38 : USB_HOST_OCP_DET_N */
	msm_gpio_38: msm_gpio_38 {
		mux {
			pins = "gpio38";
			function = "gpio";
		};

		config {
			pins = "gpio38";
			drive-strength = <2>;
			/delete-property/ bias-disable;
			/delete-property/ output-low;
			bias-pull-up;
		};
	};

	/* GPIO_39 : NC */
	msm_gpio_39: msm_gpio_39 {
		mux {
			pins = "gpio39";
			function = "gpio";
		};

		config {
			pins = "gpio39";
			drive-strength = <2>;
			bias-disable;
			output-high;
		};
	};

	/* GPIO_40 : TRAY_DET */
	msm_gpio_40: msm_gpio_40 {
		mux {
			pins = "gpio40";
			function = "gpio";
		};

		config {
			pins = "gpio40";
			drive-strength = <2>;
			bias-disable;
		};
	};

	/* GPIO_41 : BT_UART_TX */
	msm_gpio_41_active: msm_gpio_41 {
		mux {
			pins = "gpio41";
			function = "blsp_uart2";
		};

		config {
			pins = "gpio41";
			drive-strength = <2>;
			bias-disable;
		};
	};

	/* GPIO_41 : BT_UART_TX */
	msm_gpio_41_suspend: msm_gpio_41_suspend {
		mux {
			pins = "gpio41";
			function = "gpio";
		};

		config {
			pins = "gpio41";
			drive-strength = <2>;
			bias-disable;
			input-enable;
		};
	};

	/* GPIO_42 : BT_UART_RX */
	msm_gpio_42_active: msm_gpio_42 {
		mux {
			pins = "gpio42";
			function = "blsp_uart2";
		};

		config {
			pins = "gpio42";
			drive-strength = <2>;
			bias-pull-up;
		};
	};

	/* GPIO_42 : BT_UART_RX */
	msm_gpio_42_suspend: msm_gpio_42_suspend {
		mux {
			pins = "gpio42";
			function = "gpio";
		};

		config {
			pins = "gpio42";
			drive-strength = <2>;
			bias-disable;
			input-enable;
		};
	};

	/* GPIO_43 : BT_UART_CTS_N */
	msm_gpio_43_active: msm_gpio_43 {
		mux {
			pins = "gpio43";
			function = "blsp_uart2";
		};

		config {
			pins = "gpio43";
			drive-strength = <2>;
			bias-pull-up;
		};
	};

	/* GPIO_43 : BT_UART_CTS_N */
	msm_gpio_43_suspend: msm_gpio_43_suspend {
		mux {
			pins = "gpio43";
			function = "gpio";
		};

		config {
			pins = "gpio43";
			drive-strength = <2>;
			bias-disable;
			input-enable;
		};
	};

	/* GPIO_44 : BT_UART_RTS_N */
	msm_gpio_44_active: msm_gpio_44_active {
		mux {
			pins = "gpio44";
			function = "blsp_uart2";
		};

		config {
			pins = "gpio44";
			drive-strength = <2>;
			bias-disable;
		};
	};

	msm_gpio_44_suspend: msm_gpio_44_suspend {
		mux {
			pins = "gpio44";
			function = "gpio";
		};

		config {
			pins = "gpio44";
			drive-strength = <2>;
			bias-disable;
			input-enable;
		};
	};

	/* GPIO_45 : MP_UART_TX */
	msm_gpio_45_active: msm_gpio_45_active {
		mux {
			pins = "gpio45";
			function = "blsp_uart3";
		};

		config {
			pins = "gpio45";
			drive-strength = <2>;
			bias-disable;
		};
	};

	/* GPIO_45 : MP_UART_TX */
	msm_gpio_45_suspend: msm_gpio_45_suspend {
		mux {
			pins = "gpio45";
			function = "gpio";
		};

		config {
			pins = "gpio45";
			drive-strength = <2>;
			bias-pull-down;
			input-enable;
		};
	};

	/* GPIO_46 : MP_UART_RX */
	msm_gpio_46_active: msm_gpio_46_active {
		mux {
			pins = "gpio46";
			function = "blsp_uart3";
		};

		config {
			pins = "gpio46";
			drive-strength = <2>;
			bias-disable;
		};
	};

	/* GPIO_46 : MP_UART_RX */
	msm_gpio_46_suspend: msm_gpio_46_suspend {
		mux {
			pins = "gpio46";
			function = "gpio";
		};

		config {
			pins = "gpio46";
			drive-strength = <2>;
			bias-pull-down;
			input-enable;
		};
	};

	/* GPIO_47 : BT_UART_CTS_N */
	msm_gpio_47_active: msm_gpio_47_active {
		mux {
			pins = "gpio47";
			function = "blsp_uart3";
		};

		config {
			pins = "gpio47";
			drive-strength = <2>;
			bias-disable;
		};
	};

	/* GPIO_47 : BT_UART_CTS_N */
	msm_gpio_47_suspend: msm_gpio_47_suspend {
		mux {
			pins = "gpio47";
			function = "gpio";
		};

		config {
			pins = "gpio47";
			drive-strength = <2>;
			bias-pull-down;
			input-enable;
		};
	};

	/* GPIO_48 : MP_UART_RTS_N */
	msm_gpio_48_active: msm_gpio_48_active {
		mux {
			pins = "gpio48";
			function = "blsp_uart3";
		};

		config {
			pins = "gpio48";
			drive-strength = <2>;
			bias-disable;
		};
	};

	/* GPIO_48 : BT_UART_RTS_N */
	msm_gpio_48_suspend: msm_gpio_48_suspend {
		mux {
			pins = "gpio48";
			function = "gpio";
		};

		config {
			pins = "gpio48";
			drive-strength = <2>;
			bias-pull-down;
			input-enable;
		};
	};

	/* GPIO_49 : MP_DBG_UART_TX */
	msm_gpio_49: msm_gpio_49 {
		mux {
			pins = "gpio49";
			function = "blsp_uart9";
		};

		config {
			pins = "gpio49";
			drive-strength = <2>;
			bias-pull-up;
		};
	};

	/* GPIO_50 : MP_DBG_UART_RX */
	msm_gpio_50: msm_gpio_50 {
		mux {
			pins = "gpio50";
			function = "blsp_uart9";
		};

		config {
			pins = "gpio50";
			drive-strength = <2>;
			bias-disable;
			output-low;
		};
	};

	/* GPIO_51 : LCD_VDDIO_EN */
	msm_gpio_51: msm_gpio_51 {
		mux {
			pins = "gpio51";
			function = "gpio";
		};

		config {
			pins = "gpio51";
			drive-strength = <2>;
			bias-disable;
			output-low;
		};
	};

	/* GPIO_52 : MHL_FW_WAKE */
	msm_gpio_52: msm_gpio_52 {
		mux {
			pins = "gpio52";
			function = "gpio";
		};

		config {
			pins = "gpio52";
			drive-strength = <2>;
			bias-disable;
			output-low;
		};
	};

	/* GPIO_53 : CODEC_INT2_N */
	/* Follow QTI */

	/* GPIO_54 : CODEC_INT1_N */
	/* Follow QTI */

	/* GPIO_55 : APPS_I2C_SDA */
	msm_gpio_55: msm_gpio_55 {
		mux {
			pins = "gpio55";
			function = "blsp_i2c7";
		};

		config {
			pins = "gpio55";
			drive-strength = <2>;
			bias-disable;
		};
	};

	msm_gpio_55_suspend: msm_gpio_55_suspend {
		mux {
			pins = "gpio55";
			function = "blsp_i2c7";
		};

		config {
			pins = "gpio55";
			drive-strength = <2>;
			bias-disable;
		};
	};

	/* GPIO_56 : APPS_I2C_SCL */
	msm_gpio_56: msm_gpio_56 {
		mux {
			pins = "gpio56";
			function = "blsp_i2c7";
		};

		config {
			pins = "gpio56";
			drive-strength = <2>;
			bias-disable;
		};
	};

	msm_gpio_56_suspend: msm_gpio_56_suspend {
		mux {
			pins = "gpio56";
			function = "blsp_i2c7";
		};

		config {
			pins = "gpio56";
			drive-strength = <2>;
			bias-disable;
		};
	};

	/* GPIO_57 : FORCED_USB_BOOT */
	msm_gpio_57: msm_gpio_57 {
		mux {
			pins = "gpio57";
			function = "gpio";
		};

		config {
			pins = "gpio57";
			drive-strength = <2>;
			bias-pull-down;
		};
	};

	/* GPIO_58 : TS_BODY_FWUP */
	msm_gpio_58: msm_gpio_58 {
		mux {
			pins = "gpio58";
			function = "gpio";
		};

		config {
			pins = "gpio58";
			drive-strength = <2>;
			bias-disable;
			output-low;
		};
	};

	/* GPIO_59 : USB_CC_INT_N */
	msm_gpio_59: msm_gpio_59 {
		mux {
			pins = "gpio59";
			function = "gpio";
		};

		config {
			pins = "gpio59";
			drive-strength = <2>;
			/delete-property/ bias-disable;
			/delete-property/ output-low;
			bias-pull-down;
		};
	};

	/* GPIO_60 : I2C_11 SDA */
	msm_gpio_60: msm_gpio_60 {
		mux {
			pins = "gpio60";
			function = "blsp_i2c11";
		};

		config {
			pins = "gpio60";
			drive-strength = <2>;
			bias-disable;
		};
	};

	/* GPIO_61 : I2C_11 SCL */
	msm_gpio_61: msm_gpio_61 {
		mux {
			pins = "gpio61";
			function = "blsp_i2c11";
		};

		config {
			pins = "gpio61";
			drive-strength = <2>;
			bias-disable;
		};
	};

	/* GPIO_62 : MHL_RST_N */
	msm_gpio_62: msm_gpio_62 {
		mux {
			pins = "gpio62";
			function = "gpio";
		};

		config {
			pins = "gpio62";
			drive-strength = <2>;
			bias-disable;
			output-low;
		};
	};

	/* GPIO_63 : P_SENSE_INT_N */
	msm_gpio_63: msm_gpio_63 {
		mux {
			pins = "gpio63";
			function = "gpio";
		};

		config {
			pins = "gpio63";
			drive-strength = <2>;
			/delete-property/ bias-disable;
			/delete-property/ output-low;
			bias-pull-up;
		};
	};

	/* GPIO_64 : CODEC_RST_N */
	/* Follow QTI */

	/* GPIO_65 : BT_PCM_CLK */
	/* Follow QTI */

	/* GPIO_66 : BT_PCM_SYNC */
	/* Follow QTI */

	/* GPIO_67 : BT_PCM_DIN */
	/* Follow QTI */

	/* GPIO_68 : BT_PCM_DOUT */
	/* Follow QTI */

	/* GPIO_69 : TOF_LD_EN */
	msm_gpio_69: msm_gpio_69 {
		mux {
			pins = "gpio69";
			function = "gpio";
		};

		config {
			pins = "gpio69";
			drive-strength = <2>;
			bias-disable;
			output-low;
		};
	};

	/* GPIO_70 : SLIMBUS_CLK */
	/* Follow QTI */

	/* GPIO_71 : SLIMBUS_DATA0 */
	/* Follow QTI */

	/* GPIO_72 : SLIMBUS_DATA1 */
	/* Follow QTI */

	/* GPIO_73 : DTV_RST_N */
	msm_gpio_73: msm_gpio_73 {
		mux {
			pins = "gpio73";
			function = "gpio";
		};

		config {
			pins = "gpio73";
			drive-strength = <2>;
			bias-disable;
			output-low;
		};
	};

	/* GPIO_74 : DTV_LDO_EN */
	msm_gpio_74: msm_gpio_74 {
		mux {
			pins = "gpio74";
			function = "gpio";
		};

		config {
			pins = "gpio74";
			drive-strength = <2>;
			bias-disable;
			output-low;
		};
	};

	/* GPIO_75 : HW_ID[0] */
	msm_gpio_75: msm_gpio_75 {
		mux {
			pins = "gpio75";
			function = "gpio";
		};

		config {
			pins = "gpio75";
			drive-strength = <2>;
			bias-pull-up;
		};
	};

	/* GPIO_76 : HW_ID[1] */
	msm_gpio_76: msm_gpio_76 {
		mux {
			pins = "gpio76";
			function = "gpio";
		};

		config {
			pins = "gpio76";
			drive-strength = <2>;
			bias-pull-up;
		};
	};

	/* GPIO_77 : TS_HEAD_INT */
	msm_gpio_77: msm_gpio_77 {
		mux {
			pins = "gpio77";
			function = "gpio";
		};

		config {
			pins = "gpio77";
			drive-strength = <2>;
			bias-pull-down;
			input-enable;
		};
	};

	/* GPIO_78 : ACC_COVER_OPEN */
	msm_gpio_78: msm_gpio_78 {
		mux {
			pins = "gpio78";
			function = "gpio";
		};

		config {
			pins = "gpio78";
			drive-strength = <2>;
			bias-pull-up;
		};
	};

	/* GPIO_79 : WL_HOST_WAKE */
	msm_gpio_79: msm_gpio_79 {
		mux {
			pins = "gpio79";
			function = "gpio";
		};

		config {
			pins = "gpio79";
			drive-strength = <2>;
			bias-pull-down;
		};
	};

	/* GPIO_80 : ACV_DETECTION */
        msm_gpio_80: msm_gpio_80 {
	        mux {
			pins = "gpio80";
			function = "gpio";
		};

		config {
			pins = "gpio80";
			drive-strength = <2>;
			bias-pull-up;
			input-enable;
		};
	};

	/* GPIO_81 : BT_DEV_WAKE */
	msm_gpio_81: msm_gpio_81 {
		mux {
			pins = "gpio81";
			function = "gpio";
		};

		config {
			pins = "gpio81";
			drive-strength = <2>;
			bias-disable;
			output-low;
		};
	};

	/* GPIO_82 : BT_HOST_WAKE */
	msm_gpio_82_active: msm_gpio_82_active {
		mux {
			pins = "gpio82";
			function = "gpio";
		};

		config {
			pins = "gpio82";
			drive-strength = <2>;
			bias-disable;
		};
	};
	msm_gpio_82_suspend: msm_gpio_82_suspend {
		mux {
			pins = "gpio82";
			function = "gpio";
		};

		config {
			pins = "gpio82";
			drive-strength = <2>;
			bias-pull-down;
		};
	};

	/* GPIO_83 : BT_REG_ON */
	msm_gpio_83: msm_gpio_83 {
		mux {
			pins = "gpio83";
			function = "gpio";
		};

		config {
			pins = "gpio83";
			drive-strength = <2>;
			bias-disable;
			output-low;
		};
	};

	/* GPIO_84 : WL_REG_ON */
	msm_gpio_84: msm_gpio_84 {
		mux {
			pins = "gpio84";
			function = "gpio";
		};

		config {
			pins = "gpio84";
			drive-strength = <2>;
			bias-disable;
			output-high;
		};
	};

	/* GPIO_85 : NC */
	msm_gpio_85: msm_gpio_85 {
		mux {
			pins = "gpio85";
			function = "gpio";
		};

		config {
			pins = "gpio85";
			drive-strength = <2>;
			bias-disable;
			output-low;
		};
	};

	/* GPIO_86 : NC */
	msm_gpio_86: msm_gpio_86 {
		mux {
			pins = "gpio86";
			function = "gpio";
		};

		config {
			pins = "gpio86";
			drive-strength = <2>;
			bias-disable;
			output-low;
		};
	};

	/* GPIO_87 : TS_I2C_SDA (Reserved for TS_SPI_CS_N) */
	msm_gpio_87: msm_gpio_87 {
		mux {
			pins = "gpio87";
			function = "blsp_i2c12";
		};

		config {
			pins = "gpio87";
			drive-strength = <2>;
			bias-disable;
		};
	};

	msm_gpio_87_act: msm_gpio_87_act {
		mux {
			pins = "gpio87";
			function = "blsp_i2c12";
		};

		config {
			pins = "gpio87";
			drive-strength = <2>;
			bias-disable;
		};
	};
	msm_gpio_87_sus: msm_gpio_87_sus {
		mux {
			pins = "gpio87";
			function = "blsp_i2c12";
		};

		config {
			pins = "gpio87";
			drive-strength = <2>;
			bias-disable;
		};
	};

	/* GPIO_88 : TS_I2C_SCL (Reserved for TS_SPI_CLK) */
	msm_gpio_88: msm_gpio_88 {
		mux {
			pins = "gpio88";
			function = "blsp_i2c12";
		};

		config {
			pins = "gpio88";
			drive-strength = <2>;
			bias-disable;
		};
	};

	msm_gpio_88_act: msm_gpio_88_act {
		mux {
			pins = "gpio88";
			function = "blsp_i2c12";
		};

		config {
			pins = "gpio88";
			drive-strength = <2>;
			bias-disable;
		};
	};

	msm_gpio_88_sus: msm_gpio_88_sus {
		mux {
			pins = "gpio88";
			function = "blsp_i2c12";
		};

		config {
			pins = "gpio88";
			drive-strength = <2>;
			bias-disable;
		};
	};

	/* GPIO_89 : TS_BODY_RESET_N */
	msm_gpio_89: msm_gpio_89 {
		mux {
			pins = "gpio89";
			function = "gpio";
		};

		config {
			pins = "gpio89";
			drive-strength = <2>;
			bias-disable;
			output-low;
		};
	};

	/* GPIO_90 : NC */
	msm_gpio_90: msm_gpio_90 {
		mux {
			pins = "gpio90";
			function = "gpio";
		};

		config {
			pins = "gpio90";
			drive-strength = <4>;
			bias-disable;
			output-low;
		};
	};


	/* GPIO_97 : GRFC0 */
	/* Follow QTI */

	/* GPIO_98 : GRFC1 */
	/* Follow QTI */

	/* GPIO_99 : GRFC2 (BOOT_CONFIG(15),   FORCE_MSA_AUTH_EN ) */
	/* Follow QTI */

	/* GPIO_100 : MAIN_ANT_SW_SEL (GRFC3) */
	/* Follow QTI */

	/* GPIO_101 : GRFC4 (WATCHDOG_DISABLE) */
	/* Follow QTI */

	/* GPIO_102 : DIV_ANT_SW_SEL (GRFC5) (BOOT_CONFIG_1) */
	/* Follow QTI */

	/* GPIO_103 : GRFC6 (BOOT_CONFIG_2) */
	/* Follow QTI */

	/* GPIO_104 : PROX_BAND_SEL (GRFC7) (BOOT_CONFIG_3) */
	/* Follow QTI */

	/* GPIO_105 : LTE */
	msm_gpio_105: msm_gpio_105 {
		mux {
			pins = "gpio105";
			function = "gpio";
		};

		config {
			pins = "gpio105";
			drive-strength = <2>;
			bias-pull-down;
		};
	};

	/* GPIO_106 : UIM2_CLK */
	/* Follow QTI */

	/* GPIO_107 : UIM2_RESET_MSM */
	/* Follow QTI */

	/* GPIO_108 : UIM2_PRESENT */
	msm_gpio_108: msm_gpio_108 {
		mux {
			pins = "gpio108";
			function = "gpio";
		};

		config {
			pins = "gpio108";
			drive-strength = <2>;
			bias-disable;
		};
	};

	/* GPIO_109 : UIM1_DATA */
	/* Follow QTI */

	/* GPIO_110 : LTE */
	msm_gpio_110: msm_gpio_110 {
		mux {
			pins = "gpio110";
			function = "gpio";
		};

		config {
			pins = "gpio110";
			drive-strength = <2>;
			bias-disable;
			output-low;
		};
	};

	/* GPIO_111 : LTE */
	msm_gpio_111: msm_gpio_111 {
		mux {
			pins = "gpio111";
			function = "gpio";
		};

		config {
			pins = "gpio111";
			drive-strength = <2>;
			bias-disable;
			output-low;
		};
	};

	/* GPIO_112 : UIM1_PRESENT */
	msm_gpio_112: msm_gpio_112 {
		mux {
			pins = "gpio112";
			function = "gpio";
		};

		config {
			pins = "gpio112";
			drive-strength = <2>;
			bias-disable;
		};
	};

	/* GPIO_113 : BATT_UICC_ALARM */
	/* Follow QTI */

	/* GPIO_114 : GRFC8 (BOOT_CONFIG_4) */
	/* Follow QTI */

	/* GPIO_115 : GRFC9 */
	/* Follow QTI */

	/* GPIO_116 : NC(TX_GTR_THRESH / GRFC_10) */
	msm_gpio_116: msm_gpio_116 {
		mux {
			pins = "gpio116";
			function = "gpio";
		};

		config {
			pins = "gpio116";
			drive-strength = <2>;
			bias-disable;
			output-low;
		};
	};

	/* GPIO_117 : ACCEL_GYRO_INT */
	/* Follow QTI */

	/* GPIO_118 : PSD_INT_FR */
	msm_gpio_118: msm_gpio_118 {
		mux {
			pins = "gpio118";
			function = "gpio";
		};

		config {
			pins = "gpio118";
			drive-strength = <2>;
			bias-pull-up;
			input-enable;
		};
	};

	/* GPIO_119 : PSD_INT_FL */
	msm_gpio_119: msm_gpio_119 {
		mux {
			pins = "gpio119";
			function = "gpio";
		};

		config {
			pins = "gpio119";
			drive-strength = <2>;
			bias-pull-up;
			input-enable;
		};
	};

	/* GPIO_120 : ALS_PROX_INT_N */
	/* Follow QTI */

	/* GPIO_121 : BACKLIGHT_EN */
	msm_gpio_121: msm_gpio_121 {
		mux {
			pins = "gpio121";
			function = "gpio";
		};

		config {
			pins = "gpio121";
			drive-strength = <2>;
			bias-disable;
			output-low;
		};
	};

	/* GPIO_122 : NC (Reserved for LCD_ID) */
	msm_gpio_122: msm_gpio_122 {
		mux {
			pins = "gpio122";
			function = "gpio";
		};

		config {
			pins = "gpio122";
			drive-strength = <2>;
			/delete-property/ bias-disable;
			/delete-property/ output-low;
			bias-pull-up;
		};
	};

	/* GPIO_123 : RF_LCD_ID_EN */
	msm_gpio_123: msm_gpio_123 {
		mux {
			pins = "gpio123";
			function = "gpio";
		};

		config {
			pins = "gpio123";
			drive-strength = <2>;
			bias-disable;
			output-low;
		};
	};

	/* GPIO_124 : NC (TP for EXT_KEYBRD_DET) */
	msm_gpio_124: msm_gpio_124 {
		mux {
			pins = "gpio124";
			function = "gpio";
		};

		config {
			pins = "gpio124";
			drive-strength = <2>;
			/delete-property/ bias-disable;
			/delete-property/ output-low;
			bias-pull-up;
		};
	};

	/* GPIO_125 : TS_BODY_INT_N */
	msm_gpio_125: msm_gpio_125 {
		mux {
			pins = "gpio125";
			function = "gpio";
		};

		config {
			pins = "gpio125";
			drive-strength = <2>;
			bias-pull-up;
			input-enable;
		};
	};

	/* GPIO_126 : PROX_DET */
	msm_gpio_126: msm_gpio_126 {
		mux {
			pins = "gpio126";
			function = "gpio";
		};

		config {
			pins = "gpio126";
			drive-strength = <2>;
			bias-disable;
			output-low;
		};
	};

	/* GPIO_127 : TS_BODY_SWDCLK */
	msm_gpio_127: msm_gpio_127 {
		mux {
			pins = "gpio127";
			function = "gpio";
		};

		config {
			pins = "gpio127";
			drive-strength = <2>;
			bias-disable;
			output-low;
		};
	};

	/* GPIO_128 : TS_BODY_SWDIO */
	msm_gpio_128: msm_gpio_128 {
		mux {
			pins = "gpio128";
			function = "gpio";
		};

		config {
			pins = "gpio128";
			drive-strength = <2>;
			bias-disable;
			output-low;
		};
	};

	/* GPIO_129 : EXT_GPS_LNA_EN (GRFC13) */
	/* Follow QTI */

	/* GPIO_130 : USB_DETECT_WEAK */
	msm_gpio_130: msm_gpio_130 {
		mux {
			pins = "gpio130";
			function = "gpio";
		};

		config {
			pins = "gpio130";
			drive-strength = <2>;
			bias-disable;
			output-low;
		};
	};

	/* GPIO_131 : USB_CABLE_DET_N */
	msm_gpio_131: msm_gpio_131 {
		mux {
			pins = "gpio131";
			function = "gpio";
		};

		config {
			pins = "gpio131";
			drive-strength = <2>;
			/delete-property/ bias-disable;
			/delete-property/ output-low;
			bias-pull-down;
		};
	};

	/* GPIO_132 : FP_INT_N */
	msm_gpio_132: msm_gpio_132 {
		mux {
			pins = "gpio132";
			function = "gpio";
		};

		config {
			pins = "gpio132";
			drive-strength = <2>;
			bias-pull-down;
		};
	};

	/* GPIO_133 : GRFC14 */
	/* Follow QTI */

	/* GPIO_134 : GSM_TX1_PHASE_D */
	/* Follow QTI */

	/* GPIO_135 : NC */
	/* Follow QTI */

	/* GPIO_136 : NC */
	/* Follow QTI */

	/* GPIO_137 : RFFE3_DATA */
	msm_gpio_137: msm_gpio_137 {
		mux {
			pins = "gpio137";
			function = "gpio";
		};

		config {
			pins = "gpio137";
			drive-strength = <2>;
			bias-disable;
			output-low;
		};
	};

	/* GPIO_138 : RFFE3_CLK */
	msm_gpio_138: msm_gpio_138 {
		mux {
			pins = "gpio138";
			function = "gpio";
		};

		config {
			pins = "gpio138";
			drive-strength = <2>;
			bias-disable;
			output-low;
		};
	};

	/* GPIO_139 : RFFE4_DATA */
	msm_gpio_139: msm_gpio_139 {
		mux {
			pins = "gpio139";
			function = "gpio";
		};

		config {
			pins = "gpio139";
			drive-strength = <2>;
			bias-disable;
			output-low;
		};
	};

	/* GPIO_140 : RFFE4_CLK */
	/* Follow QTI */

	/* GPIO_141 : NC */
	msm_gpio_141: msm_gpio_141 {
		mux {
			pins = "gpio141";
			function = "gpio";
		};

		config {
			pins = "gpio141";
			drive-strength = <2>;
			bias-disable;
			output-low;
		};
	};

	/* GPIO_142 : NC */
	msm_gpio_142: msm_gpio_142 {
		mux {
			pins = "gpio142";
			function = "gpio";
		};

		config {
			pins = "gpio142";
			drive-strength = <2>;
			bias-disable;
			output-low;
		};
	};

	/* GPIO_143 : NC */
	msm_gpio_143: msm_gpio_143 {
		mux {
			pins = "gpio143";
			function = "gpio";
		};

		config {
			pins = "gpio143";
			drive-strength = <2>;
			bias-disable;
			output-low;
		};
	};

	/* GPIO_144 : LTE_COEX_TX */
	/* Follow QTI */

	/* GPIO_145 : LTE_COEX_RX */
	/* Follow QTI */

	/* GPIO_146 : RFFE2_DATA */
	/* Follow QTI */

	/* GPIO_147 : RFFE2_CLK */
	/* Follow QTI */

	/* GPIO_148 : RFFE1_DATA */
	/* Follow QTI */

	/* GPIO_149 : RFFE1_CLK */
	/* Follow QTI */

	mdss_touch_active: mdss_touch_active {
		mux {
			pins = "gpio125";
			function = "touch_int_n";
		};
		config {
			pins = "gpio125";
			drive-strength = <2>;
			bias-pull-up;
		};
	};


	mdss_touch_suspend: mdss_touch_suspend {
		mux {
			pins = "gpio125";
			function = "touch_int_n";
		};
		config {
			pins = "gpio125";
			drive-strength = <2>;
			bias-pull-down;
		};
	};

	cam_sensor_mclk0_active: cam_sensor_mclk0_active {
		/* MCLK0 */
		mux {
			pins = "gpio13";
			function = "cam_mclk";
		};

		config {
			pins = "gpio13";
			bias-disable; /* No PULL */
			drive-strength = <4>; /* 4 MA */
		};
	};

	cam_sensor_mclk0_suspend: cam_sensor_mclk0_suspend {
		/* MCLK0 */
		mux {
			pins = "gpio13";
			function = "cam_mclk";
		};

		config {
			pins = "gpio13";
			bias-pull-down; /* PULL DOWN */
			drive-strength = <4>; /* 4 MA */
		};
	};

	cam_sensor_mclk1_active: cam_sensor_mclk1_active {
		/* MCLK1 */
		mux {
			pins = "gpio14";
			function = "cam_mclk";
		};

		config {
			pins = "gpio14";
			bias-disable; /* No PULL */
			drive-strength = <10>; /* 10 MA */
		};
	};

	cam_sensor_mclk1_suspend: cam_sensor_mclk1_suspend {
		/* MCLK1 */
		mux {
			pins = "gpio14";
			function = "cam_mclk";
		};

		config {
			pins = "gpio14";
			bias-pull-down; /* PULL DOWN */
			drive-strength = <10>; /* 10 MA */
		};
	};

	cam_sensor_mclk2_active: cam_sensor_mclk2_active {
		/* MCLK2 */
		mux {
			pins = "gpio15";
			function = "cam_mclk";
		};

		config {
			pins = "gpio15";
			bias-disable; /* No PULL */
			drive-strength = <10>; /* 10 MA */
		};
	};

	cam_sensor_mclk2_suspend: cam_sensor_mclk2_suspend {
		/* MCLK2 */
		mux {
			pins = "gpio15";
			function = "cam_mclk";
		};

		config {
			pins = "gpio15";
			bias-pull-down; /* PULL DOWN */
			drive-strength = <10>; /* 10 MA */
		};
	};

	cam_sensor_rear_active: cam_sensor_rear_active {
		/* RESET */
		mux {
			pins = "gpio30";
			function = "gpio";
		};

		config {
			pins = "gpio30";
			bias-disable; /* No PULL */
			drive-strength = <2>; /* 2 MA */
		};
	};

	cam_sensor_rear_suspend: cam_sensor_rear_suspend {
		/* RESET */
		mux {
			pins = "gpio30";
			function = "gpio";
		};

		config {
			pins = "gpio30";
			bias-disable; /* No PULL */
			drive-strength = <2>; /* 2 MA */
		};
	};

	cam_sensor_front_active: cam_sensor_front_active {
		/* RESET */
		mux {
			pins = "gpio23";
			function = "gpio";
		};

		config {
			pins = "gpio23";
			bias-disable; /* No PULL */
			drive-strength = <2>; /* 2 MA */
		};
	};

	cam_sensor_front_suspend: cam_sensor_front_suspend {
		/* RESET */
		mux {
			pins = "gpio23";
			function = "gpio";
		};

		config {
			pins = "gpio23";
			bias-disable; /* No PULL */
			drive-strength = <2>; /* 2 MA */
		};
	};

	cam_sensor_front2_active: cam_sensor_front2_active {
		/* RESET, HV_PWR_EN, LD_PWR_EN */
		mux {
			pins = "gpio26","gpio8","gpio69";
			function = "gpio";
		};

		config {
			pins = "gpio26","gpio8","gpio69";
			bias-disable; /* No PULL */
			drive-strength = <2>; /* 2 MA */
		};
	};

	cam_sensor_front2_suspend: cam_sensor_front2_suspend {
		/* RESET, HV_PWR_EN, LD_PWR_EN */
		mux {
			pins = "gpio26","gpio8","gpio69";
			function = "gpio";
		};

		config {
			pins = "gpio26","gpio8","gpio69";
			bias-disable; /* No PULL */
			drive-strength = <2>; /* 2 MA */
		};
	};

	sdc4_clk_on: sdc4_clk_on {
		mux {
			pins = "gpio93";
			function = "sdc4_clk";
		};
		config {
			pins = "gpio93";
			bias-disable; /* NO pull */
			drive-strength = <12>; /* 12 MA */
		};
	};

	sdc4_clk_off: sdc4_clk_off {
		mux {
			pins = "gpio93";
			function = "sdc4_clk";
		};
		config {
			pins = "gpio93";
			bias-disable; /* NO pull */
			drive-strength = <2>; /* 2 MA */
		};
	};

	sdc4_cmd_on: sdc4_cmd_on {
		mux {
			pins = "gpio91";
			function = "sdc4_cmd";
		};
		config {
			pins = "gpio91";
			bias-pull-up; /* pull up */
			drive-strength = <8>; /* 8 MA */
		};
	};

	sdc4_cmd_off: sdc4_cmd_off {
		mux {
			pins = "gpio91";
			function = "sdc4_cmd";
		};
		config {
			pins = "gpio91";
			bias-pull-up; /* pull up */
			drive-strength = <2>; /* 2 MA */
		};
	};

	sdc4_data0_on: data0_on {
		mux {
			pins = "gpio96";
			function = "sdc40";
		};
		config {
			pins = "gpio96";
			drive-strength = <8>;
			bias-pull-up;
		};
	};

	sdc4_data0_off: data0_off {
		mux {
			pins = "gpio96";
			function = "sdc40";
		};

		config {
			pins = "gpio96";
			drive-strength = <2>;
			bias-pull-up;
		};
	};

	sdc4_data1_on: data1_on {
		mux {
			pins = "gpio95";
			function = "sdc41";
		};

		config {
			pins = "gpio95";
			drive-strength = <8>;
			bias-pull-up;
		};
	};

	sdc4_data1_off: data1_off {
		mux {
			pins = "gpio95";
			function = "sdc41";
		};

		config {
			pins = "gpio95";
			drive-strength = <2>;
			bias-pull-up;
		};
	};

	sdc4_data2_on: data2_on {
		mux {
			pins = "gpio94";
			function = "sdc42";
		};

		config {
			pins = "gpio94";
			drive-strength = <8>;
			bias-pull-up;
		};
	};

	sdc4_data2_off: data2_off {
		mux {
			pins = "gpio94";
			function = "sdc42";
		};

		config {
			pins = "gpio94";
			drive-strength = <2>;
			bias-pull-up;
		};
	};

	sdc4_data3_on: data3_on {
		mux {
			pins = "gpio92";
			function = "sdc43";
		};

		config {
			pins = "gpio92";
			drive-strength = <8>;
			bias-pull-up;
		};
	};

	sdc4_data3_off: data3_off {
		mux {
			pins = "gpio92";
			function = "sdc43";
		};

		config {
			pins = "gpio92";
			drive-strength = <2>;
			bias-pull-up;
		};
	};
};

&spmi_bus {
	qcom,pm8994@0 {
		vadc@3100 {
			/* MPP_5: ALS_OUT_ANA */
			chan@14 {
				label = "mpp5_1_1";
				reg = <0x14>; /* P_MUX5_1_1, P_MUX5_1/1, MPP5 */
				qcom,decimation = <0x0>;
				qcom,pre-div-channel-scaling = <0x0>;
				qcom,calibration-type = "absolute";
				qcom,scale-function = <0x0>;
				qcom,hw-settle-time = <0x1>;
				qcom,fast-avg-setup = <0x0>;
			};

			chan@24 {
				label = "mpp5_1_3";
				reg = <0x24>; /* P_MUX5_1_3, P_MUX5_1/3, MPP5 */
				qcom,decimation = <0x0>;
				qcom,pre-div-channel-scaling = <0x1>; /* Use 1:3 scaling */
				qcom,calibration-type = "absolute";
				qcom,scale-function = <0x0>;
				qcom,hw-settle-time = <0x1>;
				qcom,fast-avg-setup = <0x0>;
			};
		};

		qcom,power-on@800 {
			interrupts = <0x0 0x8 0x0>,
				     <0x0 0x8 0x1>,
				     <0x0 0x8 0x2>,
				     <0x0 0x8 0x4>,
				     <0x0 0x8 0x5>;
			interrupt-names = "kpdpwr", "resin", "cblpwr",
					"resin-bark", "kpdpwr-resin-bark";

			qcom,s3-debounce = <16>;
			qcom,s3-src = "resin";
			qcom,pon_1 {
				/delete-property/ qcom,support-reset;
				/delete-property/ qcom,s1-timer;
				/delete-property/ qcom,s2-timer;
				/delete-property/ qcom,s2-type;
			};

                        qcom,pon_4 {
				qcom,pon-type = <2>;
				qcom,pull-up = <1>;
				linux,code = <5>;
				qcom,support-reset = <1>;
			};
		};
	};

	qcom,pmi8994@2 {
		qcom,power-on@800 {
			qcom,s3-debounce = <128>;
		};
	};

	qcom,pmi8994@3 {
		qcom,leds@d000 {
			status = "okay";
			qcom,rgb_sync = <1>;

			qcom,rgb_0 {
				somc,pwm-channel = <2>;
				qcom,pwm-max-value = <154>;
				linux,name = "led:rgb_red";
				linux,default-trigger = "none";
			};
			qcom,rgb_1 {
				somc,pwm-channel = <1>;
				qcom,pwm-max-value = <511>;
				linux,name = "led:rgb_green";
				linux,default-trigger = "none";
			};
			qcom,rgb_2 {
				somc,pwm-channel = <0>;
				qcom,pwm-max-value = <460>;
				linux,name = "led:rgb_blue";
				linux,default-trigger = "none";
			};
		};

		qcom,leds@d800 {
			qcom,led-strings-list = [00 01 02];
		};
	};
};

&sdhc_2 {
	status = "disabled";
};

#include "dsi-panel-dora.dtsi"
#include "dsi-panel-tone_cdb-1080p.dtsi"
